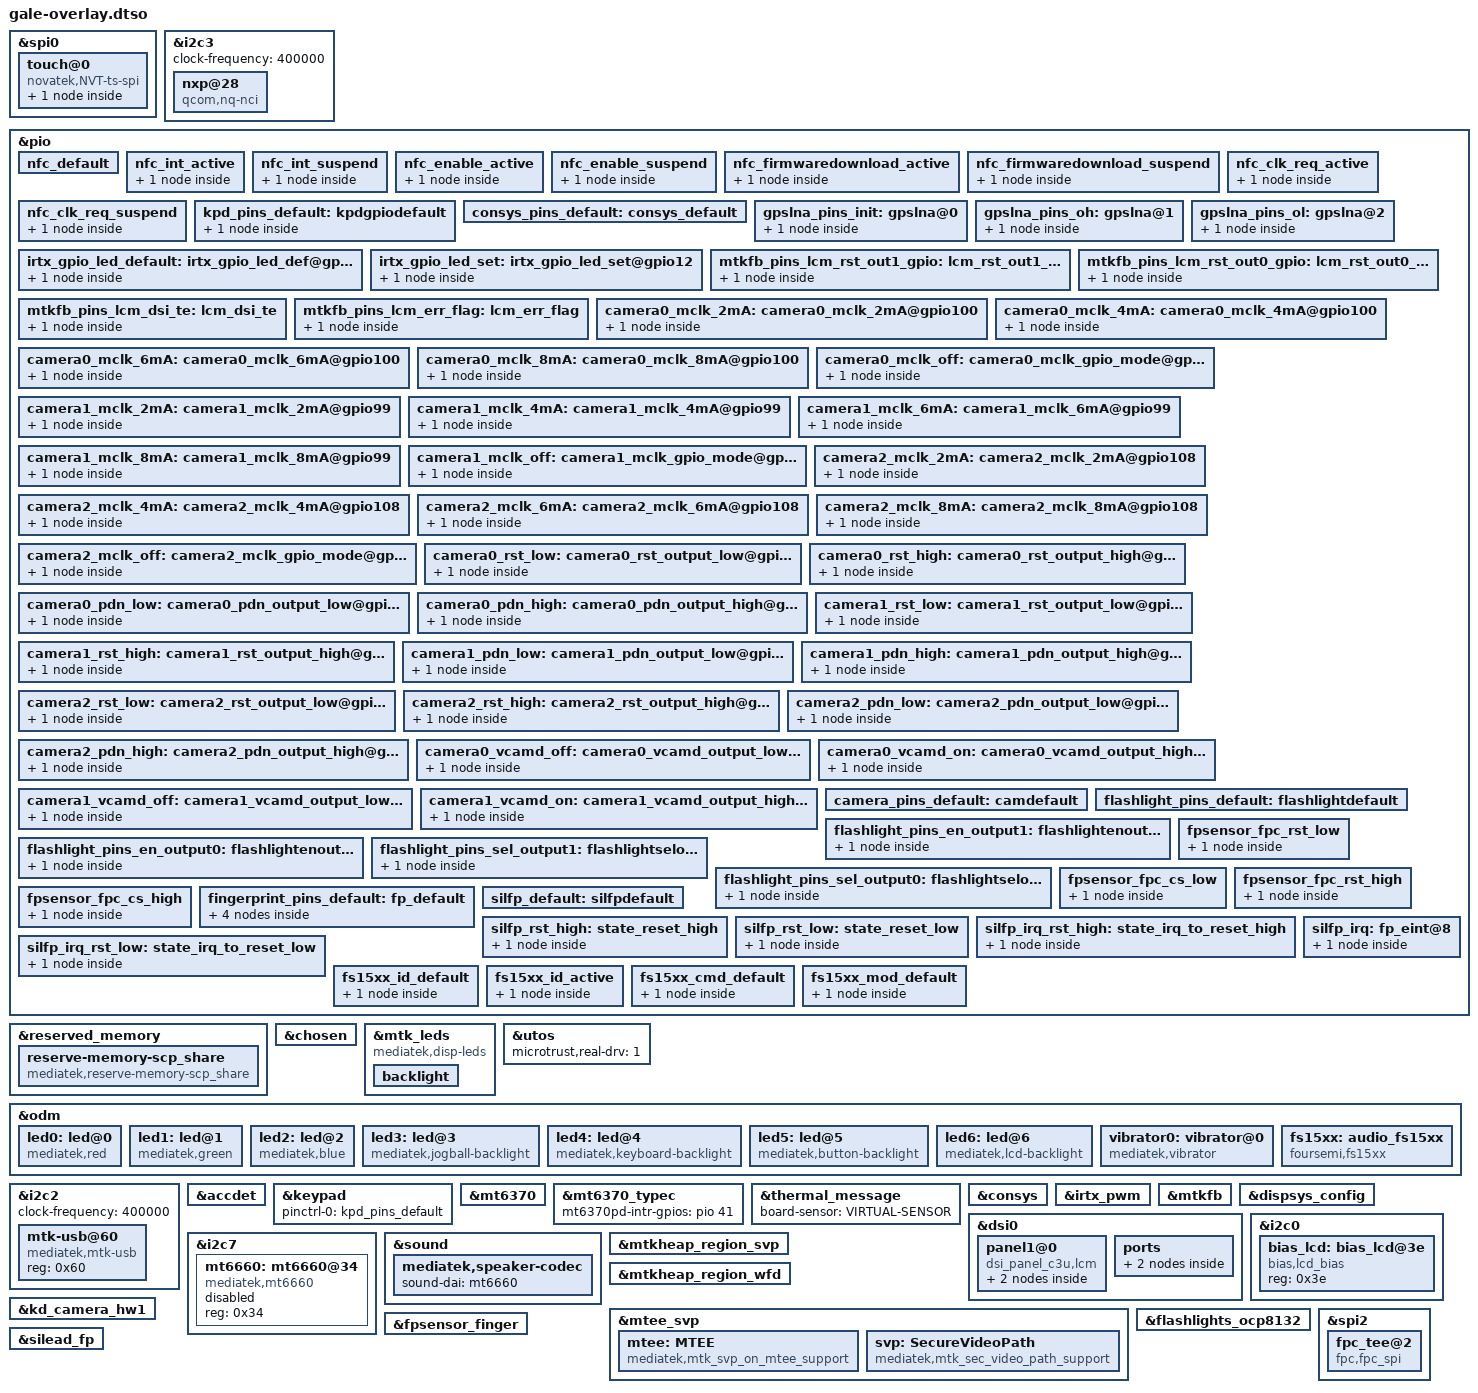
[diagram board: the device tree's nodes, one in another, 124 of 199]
// SPDX-License-Identifier: GPL-2.0
/*
 * Copyright (c) 2019 MediaTek Inc.
 */

/dts-v1/;
/plugin/;
#include <dt-bindings/interrupt-controller/irq.h>
#include <dt-bindings/interrupt-controller/arm-gic.h>
#include <dt-bindings/pinctrl/mt6768-pinfunc.h>

&spi0 {
	status = "okay";
	#address-cells = <1>;
	#size-cells = <0>;
	touch@0 {
		compatible = "novatek,NVT-ts-spi", "focaltech,fts", "omnivision,tcm-spi", "chipone-tddi";
		reg = <0x0>;
		status = "ok";
		spi-max-frequency = <0x927c00>;
		chipone,rst-gpio = <&pio 92 0>;
		chipone,irq-gpio = <&pio 1 0x2001>;
		chipone,x-res = <719>;
		chipone,y-res = <1599>;
		chipone,touch-charger-detect-enable;
		chipone,touch-charger-detect-type = "notify";
		chipone,touch-charger-detect-psy-name = "usb";
		chipone,touch-charger-detect-psp = "POWER_SUPPLY_PROP_ONLINE";
		chipone,touch-charger-detect-psp-poll-interval = <1000>;
		chipone,touch-earjack-detect-enable;
		chipone,touch-earjack-state-filepath = "/sys/bus/platform/drivers/Accdet_Driver/state";
		chipone,touch-earjack-poll-interval = <1000>;
		chipone,test-reset-pin;
		chipone,test-int-pin;
		chipone,test-rawdata;
		chipone,test-rawdata-frames = <1>;
		chipone,rawdata-min = <100>;
		chipone,rawdata-max = <10000>;
		chipone,test-noise;
		chipone,test-noise-frames = <50>;
		chipone,noise-max = <1000>;
		chipone,test-open;
		chipone,open-min = <200>;
		chipone,test-short;
		chipone,short-min = <200>;
		chipone,test-compensate-cap;
		chipone,compensate-cap-min = <1>;
		chipone,compensate-cap-max = <127>;
		chipone,test-gesture-rawdata;
		chipone,test-gesture-rawdata-frames = <1>;
		chipone,gesture-rawdata-min = <100>;
		chipone,gesture-rawdata-max = <10000>;
		chipone,test-gesture-lp-rawdata;
		chipone,test-gesture-lp-rawdata-frames = <1>;
		chipone,gesture-lp-rawdata-min = <100>;
		chipone,gesture-lp-rawdata-max = <10000>;
		chipone,test-gesture-noise;
		chipone,test-gesture-noise-frames = <50>;
		chipone,gesture-noise-max = <1000>;
		chipone,test-gesture-lp-noise;
		chipone,test-gesture-lp-noise-frames = <50>;
		chipone,gesture-lp-noise-max = <1000>;
		focaltech,reset-gpio = <&pio 92 0>;
		focaltech,irq-gpio = <&pio 1 0x2001>;
		focaltech,max-touch-number = <10>;
		focaltech,display-coords = <0 0 719 1599>;
		novatek,reset-gpio = <&pio 92 0>;
		novatek,irq-gpio = <&pio 1 0x2001>;
		novatek,mp-support-dt;
		omnivision,irq-gpio = <&pio 1 0x2001>;
		omnivision,reset-gpio = <&pio 92 0>;
		omnivision,spi-mode = <3>;
		novatek-mp-criteria-597D@0 {
			#address-cells = <1>;
			#size-cells = <0>;
			compatible = "novatek-mp-criteria-597D";
			IC_X_CFG_SIZE = <18>;
			IC_Y_CFG_SIZE = <32>;
			IC_KEY_CFG_SIZE = <4>;
			X_Channel = <18>;
			Y_Channel = <32>;
			AIN_X = <0 1 2 3 4 5 6 7 8 9 10 11 12 13 14 15 16 17>;
			AIN_Y = <0 1 2 3 4 5 6 7 8 9 10 11 12 13 14 15 16 17 18 19 20 21 22 23 24 25 26 27 28 29 30 31>;
			AIN_KEY = <0 1 2 255>;
			PS_Config_Lmt_Short_Rawdata_P = <0x36b8 0x36b8 0x36b8 0x36b8 0x36b8 0x36b8 0x36b8 0x36b8 0x36b8 0x36b8 0x36b8 0x36b8 0x36b8 0x36b8 0x36b8 0x36b8 0x36b8 0x36b8 0x36b8 0x36b8 0x36b8 0x36b8 0x36b8 0x36b8 0x36b8 0x36b8 0x36b8 0x36b8 0x36b8 0x36b8 0x36b8 0x36b8 0x36b8 0x36b8 0x36b8 0x36b8 0x36b8 0x36b8 0x36b8 0x36b8 0x36b8 0x36b8 0x36b8 0x36b8 0x36b8 0x36b8 0x36b8 0x36b8 0x36b8 0x36b8 0x36b8 0x36b8 0x36b8 0x36b8 0x36b8 0x36b8 0x36b8 0x36b8 0x36b8 0x36b8 0x36b8 0x36b8 0x36b8 0x36b8 0x36b8 0x36b8 0x36b8 0x36b8 0x36b8 0x36b8 0x36b8 0x36b8 0x36b8 0x36b8 0x36b8 0x36b8 0x36b8 0x36b8 0x36b8 0x36b8 0x36b8 0x36b8 0x36b8 0x36b8 0x36b8 0x36b8 0x36b8 0x36b8 0x36b8 0x36b8 0x36b8 0x36b8 0x36b8 0x36b8 0x36b8 0x36b8 0x36b8 0x36b8 0x36b8 0x36b8 0x36b8 0x36b8 0x36b8 0x36b8 0x36b8 0x36b8 0x36b8 0x36b8 0x36b8 0x36b8 0x36b8 0x36b8 0x36b8 0x36b8 0x36b8 0x36b8 0x36b8 0x36b8 0x36b8 0x36b8 0x36b8 0x36b8 0x36b8 0x36b8 0x36b8 0x36b8 0x36b8 0x36b8 0x36b8 0x36b8 0x36b8 0x36b8 0x36b8 0x36b8 0x36b8 0x36b8 0x36b8 0x36b8 0x36b8 0x36b8 0x36b8 0x36b8 0x36b8 0x36b8 0x36b8 0x36b8 0x36b8 0x36b8 0x36b8 0x36b8 0x36b8 0x36b8 0x36b8 0x36b8 0x36b8 0x36b8 0x36b8 0x36b8 0x36b8 0x36b8 0x36b8 0x36b8 0x36b8 0x36b8 0x36b8 0x36b8 0x36b8 0x36b8 0x36b8 0x36b8 0x36b8 0x36b8 0x36b8 0x36b8 0x36b8 0x36b8 0x36b8 0x36b8 0x36b8 0x36b8 0x36b8 0x36b8 0x36b8 0x36b8 0x36b8 0x36b8 0x36b8 0x36b8 0x36b8 0x36b8 0x36b8 0x36b8 0x36b8 0x36b8 0x36b8 0x36b8 0x36b8 0x36b8 0x36b8 0x36b8 0x36b8 0x36b8 0x36b8 0x36b8 0x36b8 0x36b8 0x36b8 0x36b8 0x36b8 0x36b8 0x36b8 0x36b8 0x36b8 0x36b8 0x36b8 0x36b8 0x36b8 0x36b8 0x36b8 0x36b8 0x36b8 0x36b8 0x36b8 0x36b8 0x36b8 0x36b8 0x36b8 0x36b8 0x36b8 0x36b8 0x36b8 0x36b8 0x36b8 0x36b8 0x36b8 0x36b8 0x36b8 0x36b8 0x36b8 0x36b8 0x36b8 0x36b8 0x36b8 0x36b8 0x36b8 0x36b8 0x36b8 0x36b8 0x36b8 0x36b8 0x36b8 0x36b8 0x36b8 0x36b8 0x36b8 0x36b8 0x36b8 0x36b8 0x36b8 0x36b8 0x36b8 0x36b8 0x36b8 0x36b8 0x36b8 0x36b8 0x36b8 0x36b8 0x36b8 0x36b8 0x36b8 0x36b8 0x36b8 0x36b8 0x36b8 0x36b8 0x36b8 0x36b8 0x36b8 0x36b8 0x36b8 0x36b8 0x36b8 0x36b8 0x36b8 0x36b8 0x36b8 0x36b8 0x36b8 0x36b8 0x36b8 0x36b8 0x36b8 0x36b8 0x36b8 0x36b8 0x36b8 0x36b8 0x36b8 0x36b8 0x36b8 0x36b8 0x36b8 0x36b8 0x36b8 0x36b8 0x36b8 0x36b8 0x36b8 0x36b8 0x36b8 0x36b8 0x36b8 0x36b8 0x36b8 0x36b8 0x36b8 0x36b8 0x36b8 0x36b8 0x36b8 0x36b8 0x36b8 0x36b8 0x36b8 0x36b8 0x36b8 0x36b8 0x36b8 0x36b8 0x36b8 0x36b8 0x36b8 0x36b8 0x36b8 0x36b8 0x36b8 0x36b8 0x36b8 0x36b8 0x36b8 0x36b8 0x36b8 0x36b8 0x36b8 0x36b8 0x36b8 0x36b8 0x36b8 0x36b8 0x36b8 0x36b8 0x36b8 0x36b8 0x36b8 0x36b8 0x36b8 0x36b8 0x36b8 0x36b8 0x36b8 0x36b8 0x36b8 0x36b8 0x36b8 0x36b8 0x36b8 0x36b8 0x36b8 0x36b8 0x36b8 0x36b8 0x36b8 0x36b8 0x36b8 0x36b8 0x36b8 0x36b8 0x36b8 0x36b8 0x36b8 0x36b8 0x36b8 0x36b8 0x36b8 0x36b8 0x36b8 0x36b8 0x36b8 0x36b8 0x36b8 0x36b8 0x36b8 0x36b8 0x36b8 0x36b8 0x36b8 0x36b8 0x36b8 0x36b8 0x36b8 0x36b8 0x36b8 0x36b8 0x36b8 0x36b8 0x36b8 0x36b8 0x36b8 0x36b8 0x36b8 0x36b8 0x36b8 0x36b8 0x36b8 0x36b8 0x36b8 0x36b8 0x36b8 0x36b8 0x36b8 0x36b8 0x36b8 0x36b8 0x36b8 0x36b8 0x36b8 0x36b8 0x36b8 0x36b8 0x36b8 0x36b8 0x36b8 0x36b8 0x36b8 0x36b8 0x36b8 0x36b8 0x36b8 0x36b8 0x36b8 0x36b8 0x36b8 0x36b8 0x36b8 0x36b8 0x36b8 0x36b8 0x36b8 0x36b8 0x36b8 0x36b8 0x36b8 0x36b8 0x36b8 0x36b8 0x36b8 0x36b8 0x36b8 0x36b8 0x36b8 0x36b8 0x36b8 0x36b8 0x36b8 0x36b8 0x36b8 0x36b8 0x36b8 0x36b8 0x36b8 0x36b8 0x36b8 0x36b8 0x36b8 0x36b8 0x36b8 0x36b8 0x36b8 0x36b8 0x36b8 0x36b8 0x36b8 0x36b8 0x36b8 0x36b8 0x36b8 0x36b8 0x36b8 0x36b8 0x36b8 0x36b8 0x36b8 0x36b8 0x36b8 0x36b8 0x36b8 0x36b8 0x36b8 0x36b8 0x36b8 0x36b8 0x36b8 0x36b8 0x36b8 0x36b8 0x36b8 0x36b8 0x36b8 0x36b8 0x36b8 0x36b8 0x36b8 0x36b8 0x36b8 0x36b8 0x36b8 0x36b8 0x36b8 0x36b8 0x36b8 0x36b8 0x36b8 0x36b8 0x36b8 0x36b8 0x36b8 0x36b8 0x36b8 0x36b8 0x36b8 0x36b8 0x36b8 0x36b8 0x36b8 0x36b8 0x36b8 0x36b8 0x36b8 0x36b8 0x36b8 0x36b8 0x36b8 0x36b8 0x36b8 0x36b8 0x36b8 0x36b8 0x36b8 0x36b8 0x36b8 0x36b8 0x36b8 0x36b8 0x36b8 0x36b8 0x36b8 0x36b8 0x36b8 0x36b8 0x36b8 0x36b8 0x36b8 0x36b8 0x36b8 0x36b8 0x36b8 0x36b8 0x36b8 0x36b8 0x36b8 0x36b8 0x36b8 0x36b8 0x36b8 0x36b8 0x36b8 0x36b8 0x36b8>;
			PS_Config_Lmt_Short_Rawdata_N = <0x2774 0x2774 0x2774 0x2774 0x2774 0x2774 0x2774 0x2774 0x2774 0x2774 0x2774 0x2774 0x2774 0x2774 0x2774 0x2774 0x2774 0x2774 0x2774 0x2774 0x2774 0x2774 0x2774 0x2774 0x2774 0x2774 0x2774 0x2774 0x2774 0x2774 0x2774 0x2774 0x2774 0x2774 0x2774 0x2774 0x2774 0x2774 0x2774 0x2774 0x2774 0x2774 0x2774 0x2774 0x2774 0x2774 0x2774 0x2774 0x2774 0x2774 0x2774 0x2774 0x2774 0x2774 0x2774 0x2774 0x2774 0x2774 0x2774 0x2774 0x2774 0x2774 0x2774 0x2774 0x2774 0x2774 0x2774 0x2774 0x2774 0x2774 0x2774 0x2774 0x2774 0x2774 0x2774 0x2774 0x2774 0x2774 0x2774 0x2774 0x2774 0x2774 0x2774 0x2774 0x2774 0x2774 0x2774 0x2774 0x2774 0x2774 0x2774 0x2774 0x2774 0x2774 0x2774 0x2774 0x2774 0x2774 0x2774 0x2774 0x2774 0x2774 0x2774 0x2774 0x2774 0x2774 0x2774 0x2774 0x2774 0x2774 0x2774 0x2774 0x2774 0x2774 0x2774 0x2774 0x2774 0x2774 0x2774 0x2774 0x2774 0x2774 0x2774 0x2774 0x2774 0x2774 0x2774 0x2774 0x2774 0x2774 0x2774 0x2774 0x2774 0x2774 0x2774 0x2774 0x2774 0x2774 0x2774 0x2774 0x2774 0x2774 0x2774 0x2774 0x2774 0x2774 0x2774 0x2774 0x2774 0x2774 0x2774 0x2774 0x2774 0x2774 0x2774 0x2774 0x2774 0x2774 0x2774 0x2774 0x2774 0x2774 0x2774 0x2774 0x2774 0x2774 0x2774 0x2774 0x2774 0x2774 0x2774 0x2774 0x2774 0x2774 0x2774 0x2774 0x2774 0x2774 0x2774 0x2774 0x2774 0x2774 0x2774 0x2774 0x2774 0x2774 0x2774 0x2774 0x2774 0x2774 0x2774 0x2774 0x2774 0x2774 0x2774 0x2774 0x2774 0x2774 0x2774 0x2774 0x2774 0x2774 0x2774 0x2774 0x2774 0x2774 0x2774 0x2774 0x2774 0x2774 0x2774 0x2774 0x2774 0x2774 0x2774 0x2774 0x2774 0x2774 0x2774 0x2774 0x2774 0x2774 0x2774 0x2774 0x2774 0x2774 0x2774 0x2774 0x2774 0x2774 0x2774 0x2774 0x2774 0x2774 0x2774 0x2774 0x2774 0x2774 0x2774 0x2774 0x2774 0x2774 0x2774 0x2774 0x2774 0x2774 0x2774 0x2774 0x2774 0x2774 0x2774 0x2774 0x2774 0x2774 0x2774 0x2774 0x2774 0x2774 0x2774 0x2774 0x2774 0x2774 0x2774 0x2774 0x2774 0x2774 0x2774 0x2774 0x2774 0x2774 0x2774 0x2774 0x2774 0x2774 0x2774 0x2774 0x2774 0x2774 0x2774 0x2774 0x2774 0x2774 0x2774 0x2774 0x2774 0x2774 0x2774 0x2774 0x2774 0x2774 0x2774 0x2774 0x2774 0x2774 0x2774 0x2774 0x2774 0x2774 0x2774 0x2774 0x2774 0x2774 0x2774 0x2774 0x2774 0x2774 0x2774 0x2774 0x2774 0x2774 0x2774 0x2774 0x2774 0x2774 0x2774 0x2774 0x2774 0x2774 0x2774 0x2774 0x2774 0x2774 0x2774 0x2774 0x2774 0x2774 0x2774 0x2774 0x2774 0x2774 0x2774 0x2774 0x2774 0x2774 0x2774 0x2774 0x2774 0x2774 0x2774 0x2774 0x2774 0x2774 0x2774 0x2774 0x2774 0x2774 0x2774 0x2774 0x2774 0x2774 0x2774 0x2774 0x2774 0x2774 0x2774 0x2774 0x2774 0x2774 0x2774 0x2774 0x2774 0x2774 0x2774 0x2774 0x2774 0x2774 0x2774 0x2774 0x2774 0x2774 0x2774 0x2774 0x2774 0x2774 0x2774 0x2774 0x2774 0x2774 0x2774 0x2774 0x2774 0x2774 0x2774 0x2774 0x2774 0x2774 0x2774 0x2774 0x2774 0x2774 0x2774 0x2774 0x2774 0x2774 0x2774 0x2774 0x2774 0x2774 0x2774 0x2774 0x2774 0x2774 0x2774 0x2774 0x2774 0x2774 0x2774 0x2774 0x2774 0x2774 0x2774 0x2774 0x2774 0x2774 0x2774 0x2774 0x2774 0x2774 0x2774 0x2774 0x2774 0x2774 0x2774 0x2774 0x2774 0x2774 0x2774 0x2774 0x2774 0x2774 0x2774 0x2774 0x2774 0x2774 0x2774 0x2774 0x2774 0x2774 0x2774 0x2774 0x2774 0x2774 0x2774 0x2774 0x2774 0x2774 0x2774 0x2774 0x2774 0x2774 0x2774 0x2774 0x2774 0x2774 0x2774 0x2774 0x2774 0x2774 0x2774 0x2774 0x2774 0x2774 0x2774 0x2774 0x2774 0x2774 0x2774 0x2774 0x2774 0x2774 0x2774 0x2774 0x2774 0x2774 0x2774 0x2774 0x2774 0x2774 0x2774 0x2774 0x2774 0x2774 0x2774 0x2774 0x2774 0x2774 0x2774 0x2774 0x2774 0x2774 0x2774 0x2774 0x2774 0x2774 0x2774 0x2774 0x2774 0x2774 0x2774 0x2774 0x2774 0x2774 0x2774 0x2774 0x2774 0x2774 0x2774 0x2774 0x2774 0x2774 0x2774 0x2774 0x2774 0x2774 0x2774 0x2774 0x2774 0x2774 0x2774 0x2774 0x2774 0x2774 0x2774 0x2774 0x2774 0x2774 0x2774 0x2774 0x2774 0x2774 0x2774 0x2774 0x2774 0x2774 0x2774 0x2774 0x2774 0x2774 0x2774 0x2774 0x2774 0x2774 0x2774 0x2774 0x2774 0x2774 0x2774 0x2774 0x2774 0x2774 0x2774 0x2774 0x2774 0x2774 0x2774 0x2774 0x2774 0x2774 0x2774 0x2774 0x2774 0x2774 0x2774 0x2774 0x2774 0x2774 0x2774 0x2774 0x2774 0x2774 0x2774 0x2774 0x2774 0x2774 0x2774 0x2774 0x2710 0x2710 0x2710>;
			PS_Config_Lmt_Open_Rawdata_P = <0xa0b 0xa06 0x9d3 0x999 0x963 0x945 0x90e 0x8f5 0xffff 0xffff 0x811 0x821 0x840 0x852 0x874 0x88a 0x8a9 0x8cb 0x984 0x98b 0x974 0x94e 0x92b 0x914 0x904 0x8ee 0x8d7 0x918 0x922 0x92e 0x934 0x93c 0x943 0x942 0x957 0x97f 0xa43 0xa4c 0xa33 0xa0b 0x9e8 0x9ca 0x9b6 0x9a1 0x984 0x89f 0x8a8 0x8ad 0x8b9 0x8c5 0x8cf 0x8d3 0x8de 0x908 0x9b9 0x9d5 0x9c0 0x9a1 0x97f 0x962 0x94e 0x938 0x923 0x947 0x950 0x95b 0x966 0x96f 0x977 0x97b 0x98b 0x9af 0xa48 0xa6c 0xa4d 0xa2a 0x9ff 0x9dd 0x9cc 0x9ae 0x999 0x8f5 0x901 0x907 0x912 0x918 0x91c 0x924 0x937 0x95a 0x9e4 0xa0e 0x9ee 0x9cb 0x9a7 0x988 0x976 0x95f 0x94a 0x9b6 0x9c3 0x9cc 0x9d6 0x9dd 0x9e6 0x9ed 0x9fb 0xa1c 0xa4d 0xa3f 0xa18 0x9f9 0x9cc 0x9b3 0x9af 0x999 0x97e 0x924 0x92e 0x93b 0x938 0x946 0x94c 0x94d 0x96f 0x91c 0x9b6 0x9a1 0x97d 0x95e 0x935 0x91c 0x916 0x8ff 0x8e7 0x9e0 0x9e8 0x9f5 0x9f1 0xa06 0xa10 0xa15 0xa35 0x9fb 0xa8b 0xa6d 0xa49 0xa2e 0xa04 0x9e4 0x9e4 0x9c3 0x9a9 0x98b 0x999 0x99e 0x99b 0x9a4 0x9ae 0x9ac 0x9ce 0x993 0xa27 0xa06 0x9e3 0x9c3 0x99a 0x978 0x976 0x95b 0x945 0xa1b 0xa27 0xa37 0xa2e 0xa38 0xa46 0xa49 0xa62 0xa38 0xb02 0xad6 0xaae 0xa8f 0xa69 0xa4d 0xa42 0xa2a 0xa17 0x9b3 0x9bd 0x9cc 0x9cb 0x9d6 0x9e6 0x9e0 0xa02 0x9e4 0xa88 0xa61 0xa3e 0xa25 0x9fd 0x9e4 0x9d8 0x9bd 0x9a7 0xab1 0xaba 0xaca 0xac6 0xad1 0xadd 0xadc 0xafe 0xaeb 0xb6c 0xb3e 0xb1b 0xafc 0xad6 0xab8 0xaab 0xa96 0xa77 0xa49 0xa4f 0xa5f 0xa53 0xa5b 0xa66 0xa5e 0xa7d 0xa73 0xae3 0xab8 0xa93 0xa76 0xa50 0xa34 0xa2c 0xa17 0x9fc 0xa8e 0xa93 0xa9d 0xa99 0xaa4 0xaab 0xaa8 0xac7 0xac4 0xbcd 0xb9c 0xb73 0xb54 0xb30 0xb0e 0xb07 0xae9 0xad2 0xa3f 0xa4c 0xa57 0xa58 0xa5f 0xa66 0xa5f 0xa7d 0xa8c 0xb3d 0xb0d 0xae6 0xacd 0xaa5 0xa88 0xa81 0xa65 0xa50 0xb00 0xb07 0xb10 0xb0e 0xb17 0xb26 0xb2a 0xb49 0xb61 0xc2c 0xbf8 0xbcb 0xbad 0xb84 0xb62 0xb5b 0xb3d 0xb2c 0xad6 0xadd 0xae7 0xadd 0xae4 0xaf0 0xaf1 0xb11 0xb2d 0xbb2 0xb81 0xb60 0xb3f 0xb0d 0xaed 0xadd 0xac1 0xaaf 0xb5a 0xb62 0xb75 0xb73 0xb7c 0xb84 0xb84 0xba1 0xbc6 0xc8a 0xc60 0xc3d 0xc18 0xbf3 0xbce 0xbb6 0xb9f 0xb81 0xaee 0xaed 0xb02 0xafb 0xb06 0xb0e 0xb07 0xb26 0xb44 0xc1d 0xbec 0xbc9 0xba6 0xb7e 0xb68 0xb59 0xb41 0xb25 0xbbd 0xbc6 0xbd7 0xbd1 0xbd2 0xbe0 0xbdf 0xbff 0xc2c 0xcf0 0xcbc 0xc92 0xc72 0xc49 0xc34 0xc2d 0xc11 0xbed 0xb6c 0xb79 0xb83 0xb7e 0xb8a 0xb92 0xb8c 0xbab 0xbd7 0xc79 0xc48 0xc2b 0xc05 0xbdf 0xbc4 0xbbd 0xba6 0xb8a 0xc2c 0xc39 0xc47 0xc41 0xc4e 0xc59 0xc5d 0xc75 0xca3 0xd6d 0xd3a 0xd0d 0xcf1 0xcc7 0xca7 0xc9c 0xc7d 0xc63 0xbe2 0xbfb 0xc03 0xc06 0xc11 0xc1b 0xc1b 0xc36 0xc59 0xce6 0xcb2 0xc8e 0xc73 0xc4f 0xc2f 0xc1f 0xc0a 0xbf3 0xca0 0xcb2 0xcb8 0xcb7 0xcbf 0xcc9 0xcd0 0xcea 0xd19 0xdec 0xdbf 0xd99 0xd7b 0xd4f 0xd32 0xd20 0xcfe 0xcdc 0xc41 0xc4f 0xc5e 0xc57 0xc59 0xc67 0xc64 0xc83 0xcad 0xd68 0xd3d 0xd19 0xcf8 0xcce 0xcb4 0xca3 0xc8e 0xc6c 0xce9 0xcfe 0xd0b 0xd0f 0xd1a 0xd22 0xd1d 0xd35 0xd5d 0xe35 0xe08 0xddb 0xdb7 0xd8e 0xd79 0xd68 0xd51 0xd29 0xc8d 0xc9b 0xca9 0xcb0 0xcb5 0xcb8 0xcbc 0xcdf 0xd0c 0xe17 0xdec 0xdcd 0xdaa 0xd7d 0xd64 0xd56 0xd35 0xd16 0xd5f 0xd68 0xd79 0xd7b 0xd7f 0xd8b 0xd8d 0xda3 0xdd0 0xe62 0xed9 0xeb4 0xe91 0xe63 0xe3c 0xe2a 0xe09 0xddf 0xd08 0xd1a 0xd24 0xd29 0xd2e 0xd37 0xd39 0xd5f 0xd10 0xd7d 0xdf7 0xdde 0xdbc 0xd9b 0xd7d 0xd6d 0xd4e 0xd32 0xdb8 0xdc8 0xddd 0xde5 0xdef 0xdf7 0xdfb 0xe0b 0xdac 0xe75 0xf15 0xef3 0xecc 0xea3 0xe7c 0xe6b 0xe4b 0xe2a 0xd63 0xd75 0xd83 0xd7f 0xd83 0xd8e 0xd8b 0xda5 0xd3e 0xe00 0xeb1 0xeaa 0xe82 0xe5d 0xe43 0xe32 0xe1a 0xdf7 0xe01 0xe12 0xe1c 0xe20 0xe2e 0xe40 0xe47 0xe44 0xdb5 0x1400 0x1400 0x1400>;
			PS_Config_Lmt_Open_Rawdata_N = <0x44e 0x44b 0x436 0x41d 0x406 0x3f9 0x3e1 0x3d6 0xffff0001 0xffff0001 0x375 0x37c 0x389 0x391 0x39f 0x3a9 0x3b6 0x3c4 0x414 0x417 0x40d 0x3fd 0x3ee 0x3e4 0x3dd 0x3d3 0x3ca 0x3e5 0x3ea 0x3ef 0x3f1 0x3f5 0x3f8 0x3f7 0x400 0x412 0x466 0x469 0x45f 0x44e 0x43f 0x432 0x429 0x420 0x414 0x3b2 0x3b5 0x3b8 0x3bd 0x3c2 0x3c6 0x3c8 0x3cd 0x3df 0x42a 0x436 0x42d 0x420 0x412 0x405 0x3fd 0x3f3 0x3ea 0x3fa 0x3fd 0x402 0x407 0x40b 0x40e 0x410 0x417 0x426 0x468 0x477 0x46a 0x45b 0x448 0x43a 0x433 0x426 0x41d 0x3d6 0x3dc 0x3de 0x3e3 0x3e5 0x3e7 0x3eb 0x3f3 0x402 0x43d 0x44f 0x441 0x432 0x423 0x415 0x40e 0x404 0x3fb 0x429 0x42f 0x433 0x437 0x43a 0x43e 0x441 0x447 0x455 0x46a 0x464 0x453 0x446 0x433 0x428 0x426 0x41d 0x411 0x3eb 0x3ef 0x3f4 0x3f3 0x3f9 0x3fc 0x3fc 0x40b 0x3e7 0x429 0x420 0x411 0x403 0x3f2 0x3e7 0x3e5 0x3db 0x3d0 0x43b 0x43f 0x444 0x442 0x44b 0x450 0x452 0x460 0x447 0x484 0x478 0x468 0x45d 0x44b 0x43d 0x43d 0x42f 0x424 0x417 0x41d 0x41f 0x41e 0x421 0x426 0x425 0x433 0x41a 0x45a 0x44b 0x43c 0x42f 0x41d 0x40f 0x40e 0x402 0x3f9 0x454 0x45a 0x460 0x45d 0x461 0x467 0x468 0x473 0x461 0x4b7 0x4a5 0x493 0x486 0x476 0x46a 0x465 0x45b 0x453 0x428 0x42c 0x433 0x432 0x437 0x43e 0x43b 0x44a 0x43d 0x483 0x472 0x463 0x459 0x448 0x43d 0x438 0x42c 0x423 0x495 0x499 0x49f 0x49e 0x4a2 0x4a8 0x4a7 0x4b6 0x4ae 0x4e5 0x4d1 0x4c2 0x4b5 0x4a5 0x498 0x492 0x489 0x47c 0x468 0x46b 0x472 0x46c 0x470 0x475 0x471 0x47e 0x47a 0x4aa 0x498 0x488 0x47b 0x46b 0x45f 0x45c 0x453 0x447 0x486 0x488 0x48c 0x48a 0x48f 0x492 0x491 0x49e 0x49d 0x50e 0x4f9 0x4e8 0x4db 0x4cb 0x4bd 0x4ba 0x4ad 0x4a3 0x464 0x469 0x46e 0x46f 0x472 0x475 0x472 0x47e 0x485 0x4d1 0x4bc 0x4ab 0x4a1 0x490 0x483 0x480 0x474 0x46b 0x4b7 0x4ba 0x4bd 0x4bd 0x4c0 0x4c7 0x4c9 0x4d6 0x4e0 0x537 0x521 0x50e 0x501 0x4ef 0x4e1 0x4de 0x4d1 0x4c9 0x4a5 0x4a8 0x4ac 0x4a8 0x4ab 0x4b0 0x4b0 0x4be 0x4ca 0x503 0x4ee 0x4e0 0x4d2 0x4bc 0x4ae 0x4a8 0x49c 0x494 0x4dd 0x4e1 0x4e9 0x4e8 0x4ec 0x4ef 0x4ef 0x4fc 0x50b 0x55f 0x54d 0x53e 0x52f 0x51f 0x50f 0x505 0x4fb 0x4ee 0x4af 0x4ae 0x4b7 0x4b4 0x4b9 0x4bd 0x4ba 0x4c7 0x4d4 0x531 0x51c 0x50d 0x4fe 0x4ed 0x4e3 0x4dd 0x4d2 0x4c6 0x508 0x50b 0x513 0x510 0x511 0x517 0x516 0x524 0x537 0x58b 0x575 0x563 0x555 0x544 0x53b 0x538 0x52c 0x51c 0x4e5 0x4ea 0x4ef 0x4ed 0x4f2 0x4f5 0x4f3 0x500 0x513 0x558 0x543 0x537 0x526 0x516 0x50b 0x508 0x4fe 0x4f2 0x537 0x53d 0x543 0x540 0x546 0x54a 0x54c 0x556 0x56a 0x5c1 0x5ab 0x598 0x58c 0x57a 0x56c 0x567 0x55a 0x54f 0x517 0x522 0x526 0x527 0x52c 0x530 0x530 0x53b 0x54a 0x587 0x571 0x561 0x556 0x546 0x538 0x532 0x529 0x51f 0x569 0x571 0x573 0x573 0x576 0x57a 0x57d 0x589 0x59d 0x5f7 0x5e4 0x5d4 0x5c7 0x5b4 0x5a7 0x5a0 0x591 0x583 0x540 0x546 0x54d 0x54a 0x54a 0x550 0x54f 0x55c 0x56e 0x5bf 0x5ac 0x59d 0x58f 0x57d 0x571 0x56a 0x561 0x553 0x588 0x591 0x597 0x598 0x59d 0x5a1 0x59e 0x5a9 0x5ba 0x616 0x603 0x5f0 0x5e0 0x5cf 0x5c6 0x5bf 0x5b5 0x5a4 0x561 0x567 0x56d 0x570 0x572 0x573 0x575 0x584 0x597 0x60a 0x5f7 0x5ea 0x5db 0x5c8 0x5bd 0x5b7 0x5a9 0x59b 0x5bb 0x5bf 0x5c6 0x5c7 0x5c8 0x5ce 0x5ce 0x5d8 0x5eb 0x62a 0x65d 0x64d 0x63e 0x62a 0x619 0x612 0x604 0x5f2 0x595 0x59d 0x5a1 0x5a4 0x5a6 0x5aa 0x5aa 0x5bb 0x599 0x5c8 0x5fc 0x5f1 0x5e3 0x5d4 0x5c8 0x5c1 0x5b3 0x5a7 0x5e1 0x5e8 0x5f1 0x5f4 0x5f8 0x5fc 0x5fe 0x604 0x5dc 0x632 0x676 0x668 0x657 0x646 0x635 0x62e 0x620 0x612 0x5bc 0x5c4 0x5ca 0x5c8 0x5ca 0x5cf 0x5ce 0x5d9 0x5ad 0x600 0x64c 0x649 0x637 0x628 0x61c 0x615 0x60b 0x5fc 0x600 0x607 0x60c 0x60d 0x613 0x61b 0x61e 0x61d 0x5e0 0xfffffe01 0xfffffe01 0xfffffe01>;
			PS_Config_Lmt_FW_Rawdata_P = <0x464 0x45e 0x461 0x464 0x465 0x46e 0x45e 0x462 0xffff 0xffff 0x469 0x465 0x461 0x464 0x45e 0x464 0x45e 0x460 0x456 0x45b 0x460 0x461 0x462 0x459 0x459 0x462 0x454 0x462 0x45e 0x461 0x467 0x45a 0x46b 0x464 0x468 0x45e 0x464 0x45b 0x45e 0x462 0x469 0x45e 0x457 0x45d 0x45d 0x468 0x460 0x46e 0x46f 0x459 0x462 0x468 0x465 0x460 0x453 0x464 0x468 0x45d 0x464 0x45b 0x462 0x465 0x46b 0x461 0x45e 0x462 0x461 0x464 0x460 0x464 0x464 0x46c 0x461 0x461 0x464 0x462 0x464 0x461 0x45a 0x45e 0x461 0x45d 0x468 0x460 0x45e 0x465 0x456 0x45e 0x45b 0x460 0x45b 0x454 0x460 0x456 0x469 0x45e 0x465 0x465 0x460 0x45e 0x460 0x45a 0x45b 0x461 0x460 0x465 0x45e 0x464 0x468 0x45e 0x459 0x469 0x45e 0x457 0x45e 0x45b 0x45e 0x457 0x453 0x45e 0x46b 0x45a 0x464 0x45b 0x45a 0x456 0x460 0x45e 0x456 0x467 0x462 0x45d 0x461 0x461 0x45e 0x46c 0x465 0x461 0x461 0x465 0x467 0x456 0x465 0x461 0x46b 0x45d 0x46f 0x464 0x459 0x46e 0x45b 0x45e 0x462 0x464 0x465 0x457 0x462 0x45b 0x461 0x464 0x45d 0x45e 0x46b 0x460 0x46b 0x462 0x453 0x46e 0x456 0x468 0x44f 0x460 0x470 0x462 0x45d 0x460 0x45b 0x45a 0x465 0x462 0x45d 0x464 0x46e 0x45e 0x45d 0x465 0x462 0x461 0x469 0x467 0x457 0x457 0x457 0x457 0x468 0x468 0x461 0x45e 0x450 0x459 0x464 0x461 0x45b 0x464 0x46c 0x456 0x46b 0x45d 0x460 0x462 0x460 0x461 0x460 0x46c 0x45d 0x452 0x45a 0x460 0x464 0x45e 0x461 0x468 0x462 0x45b 0x465 0x46b 0x45b 0x460 0x469 0x464 0x45a 0x44d 0x46f 0x46b 0x460 0x467 0x461 0x464 0x45e 0x45a 0x45b 0x465 0x462 0x469 0x465 0x45d 0x464 0x46e 0x45a 0x46b 0x467 0x460 0x461 0x45a 0x457 0x45e 0x46c 0x462 0x461 0x467 0x468 0x461 0x46e 0x44d 0x456 0x45b 0x464 0x461 0x456 0x45e 0x454 0x461 0x465 0x45d 0x45d 0x469 0x460 0x45d 0x464 0x464 0x468 0x460 0x45d 0x457 0x462 0x45a 0x45d 0x460 0x46f 0x45d 0x459 0x461 0x453 0x469 0x462 0x464 0x464 0x45d 0x462 0x468 0x45b 0x46c 0x460 0x45e 0x46b 0x45d 0x465 0x46f 0x462 0x460 0x45e 0x454 0x465 0x462 0x454 0x45e 0x45b 0x459 0x465 0x460 0x460 0x454 0x470 0x460 0x469 0x456 0x462 0x459 0x46b 0x469 0x457 0x46c 0x462 0x464 0x46b 0x456 0x45e 0x453 0x462 0x460 0x44f 0x45e 0x45b 0x460 0x46e 0x456 0x44c 0x462 0x461 0x465 0x462 0x460 0x45b 0x465 0x467 0x454 0x45a 0x460 0x470 0x462 0x45b 0x460 0x45e 0x453 0x462 0x45d 0x461 0x459 0x45d 0x45b 0x459 0x465 0x46b 0x46f 0x461 0x450 0x45a 0x459 0x462 0x469 0x45d 0x461 0x45e 0x45e 0x452 0x45b 0x462 0x462 0x45b 0x459 0x461 0x45d 0x46b 0x45a 0x469 0x45d 0x457 0x470 0x45b 0x46b 0x467 0x45e 0x470 0x461 0x45b 0x45a 0x45e 0x465 0x460 0x462 0x465 0x464 0x460 0x46e 0x460 0x464 0x46b 0x45e 0x45a 0x457 0x45b 0x46c 0x464 0x462 0x45d 0x45e 0x467 0x456 0x453 0x46f 0x464 0x469 0x46f 0x456 0x461 0x465 0x45e 0x456 0x457 0x450 0x457 0x459 0x45e 0x45e 0x461 0x45a 0x45e 0x45b 0x465 0x45e 0x45e 0x457 0x460 0x45a 0x457 0x461 0x45e 0x460 0x459 0x464 0x467 0x467 0x46b 0x459 0x457 0x45d 0x468 0x460 0x45d 0x462 0x456 0x461 0x45e 0x45d 0x461 0x465 0x464 0x461 0x464 0x454 0x457 0x459 0x460 0x465 0x45e 0x467 0x454 0x469 0x468 0x45b 0x467 0x467 0x460 0x461 0x45b 0x462 0x45a 0x45d 0x469 0x469 0x45e 0x461 0x44b 0x464 0x461 0x462 0x460 0x469 0x464 0x468 0x45d 0x462 0x467 0x469 0x460 0x453 0x44d 0x45d 0x46c 0x46c 0x461 0x46c 0x45d 0x464 0x459 0x450 0x45a 0x465 0x475 0x476 0x457 0x467 0x45e 0x465 0x45d 0x462 0x461 0x460 0x468 0x464 0x467 0x464 0x461 0x459 0x464 0x465 0x469 0x462 0x461 0x462 0x464 0x462 0x460 0x465 0x45d 0x462 0x45d 0x468 0x459 0x454 0x462 0x462 0x45b 0x467 0x45e 0x459 0x45e 0x459 0x45b 0x459 0x460 0x464 0x46c 0x45e 0x459 0x465 0xf00 0xf00 0xf00>;
			PS_Config_Lmt_FW_Rawdata_N = <0x1e1 0x1df 0x1e0 0x1e1 0x1e2 0x1e6 0x1df 0x1e1 0xffff0001 0xffff0001 0x1e4 0x1e2 0x1e0 0x1e1 0x1df 0x1e1 0x1df 0x1e0 0x1db 0x1de 0x1e0 0x1e0 0x1e1 0x1dd 0x1dd 0x1e1 0x1db 0x1e1 0x1df 0x1e0 0x1e3 0x1dd 0x1e4 0x1e1 0x1e3 0x1df 0x1e1 0x1de 0x1df 0x1e1 0x1e4 0x1df 0x1dc 0x1de 0x1de 0x1e3 0x1e0 0x1e6 0x1e6 0x1dd 0x1e1 0x1e3 0x1e2 0x1e0 0x1da 0x1e1 0x1e3 0x1de 0x1e1 0x1de 0x1e1 0x1e2 0x1e4 0x1e0 0x1df 0x1e1 0x1e0 0x1e1 0x1e0 0x1e1 0x1e1 0x1e5 0x1e0 0x1e0 0x1e1 0x1e1 0x1e1 0x1e0 0x1dd 0x1df 0x1e0 0x1de 0x1e3 0x1e0 0x1df 0x1e2 0x1db 0x1df 0x1de 0x1e0 0x1de 0x1db 0x1e0 0x1db 0x1e4 0x1df 0x1e2 0x1e2 0x1e0 0x1df 0x1e0 0x1dd 0x1de 0x1e0 0x1e0 0x1e2 0x1df 0x1e1 0x1e3 0x1df 0x1dd 0x1e4 0x1df 0x1dc 0x1df 0x1de 0x1df 0x1dc 0x1da 0x1df 0x1e4 0x1dd 0x1e1 0x1de 0x1dd 0x1db 0x1e0 0x1df 0x1db 0x1e3 0x1e1 0x1de 0x1e0 0x1e0 0x1df 0x1e5 0x1e2 0x1e0 0x1e0 0x1e2 0x1e3 0x1db 0x1e2 0x1e0 0x1e4 0x1de 0x1e6 0x1e1 0x1dd 0x1e6 0x1de 0x1df 0x1e1 0x1e1 0x1e2 0x1dc 0x1e1 0x1de 0x1e0 0x1e1 0x1de 0x1df 0x1e4 0x1e0 0x1e4 0x1e1 0x1da 0x1e6 0x1db 0x1e3 0x1d8 0x1e0 0x1e7 0x1e1 0x1de 0x1e0 0x1de 0x1dd 0x1e2 0x1e1 0x1de 0x1e1 0x1e6 0x1df 0x1de 0x1e2 0x1e1 0x1e0 0x1e4 0x1e3 0x1dc 0x1dc 0x1dc 0x1dc 0x1e3 0x1e3 0x1e0 0x1df 0x1d9 0x1dd 0x1e1 0x1e0 0x1de 0x1e1 0x1e5 0x1db 0x1e4 0x1de 0x1e0 0x1e1 0x1e0 0x1e0 0x1e0 0x1e5 0x1de 0x1da 0x1dd 0x1e0 0x1e1 0x1df 0x1e0 0x1e3 0x1e1 0x1de 0x1e2 0x1e4 0x1de 0x1e0 0x1e4 0x1e1 0x1dd 0x1d8 0x1e6 0x1e4 0x1e0 0x1e3 0x1e0 0x1e1 0x1df 0x1dd 0x1de 0x1e2 0x1e1 0x1e4 0x1e2 0x1de 0x1e1 0x1e6 0x1dd 0x1e4 0x1e3 0x1e0 0x1e0 0x1dd 0x1dc 0x1df 0x1e5 0x1e1 0x1e0 0x1e3 0x1e3 0x1e0 0x1e6 0x1d8 0x1db 0x1de 0x1e1 0x1e0 0x1db 0x1df 0x1db 0x1e0 0x1e2 0x1de 0x1de 0x1e4 0x1e0 0x1de 0x1e1 0x1e1 0x1e3 0x1e0 0x1de 0x1dc 0x1e1 0x1dd 0x1de 0x1e0 0x1e6 0x1de 0x1dd 0x1e0 0x1da 0x1e4 0x1e1 0x1e1 0x1e1 0x1de 0x1e1 0x1e3 0x1de 0x1e5 0x1e0 0x1df 0x1e4 0x1de 0x1e2 0x1e6 0x1e1 0x1e0 0x1df 0x1db 0x1e2 0x1e1 0x1db 0x1df 0x1de 0x1dd 0x1e2 0x1e0 0x1e0 0x1db 0x1e7 0x1e0 0x1e4 0x1db 0x1e1 0x1dd 0x1e4 0x1e4 0x1dc 0x1e5 0x1e1 0x1e1 0x1e4 0x1db 0x1df 0x1da 0x1e1 0x1e0 0x1d8 0x1df 0x1de 0x1e0 0x1e6 0x1db 0x1d7 0x1e1 0x1e0 0x1e2 0x1e1 0x1e0 0x1de 0x1e2 0x1e3 0x1db 0x1dd 0x1e0 0x1e7 0x1e1 0x1de 0x1e0 0x1df 0x1da 0x1e1 0x1de 0x1e0 0x1dd 0x1de 0x1de 0x1dd 0x1e2 0x1e4 0x1e6 0x1e0 0x1d9 0x1dd 0x1dd 0x1e1 0x1e4 0x1de 0x1e0 0x1df 0x1df 0x1da 0x1de 0x1e1 0x1e1 0x1de 0x1dd 0x1e0 0x1de 0x1e4 0x1dd 0x1e4 0x1de 0x1dc 0x1e7 0x1de 0x1e4 0x1e3 0x1df 0x1e7 0x1e0 0x1de 0x1dd 0x1df 0x1e2 0x1e0 0x1e1 0x1e2 0x1e1 0x1e0 0x1e6 0x1e0 0x1e1 0x1e4 0x1df 0x1dd 0x1dc 0x1de 0x1e5 0x1e1 0x1e1 0x1de 0x1df 0x1e3 0x1db 0x1da 0x1e6 0x1e1 0x1e4 0x1e6 0x1db 0x1e0 0x1e2 0x1df 0x1db 0x1dc 0x1d9 0x1dc 0x1dd 0x1df 0x1df 0x1e0 0x1dd 0x1df 0x1de 0x1e2 0x1df 0x1df 0x1dc 0x1e0 0x1dd 0x1dc 0x1e0 0x1df 0x1e0 0x1dd 0x1e1 0x1e3 0x1e3 0x1e4 0x1dd 0x1dc 0x1de 0x1e3 0x1e0 0x1de 0x1e1 0x1db 0x1e0 0x1df 0x1de 0x1e0 0x1e2 0x1e1 0x1e0 0x1e1 0x1db 0x1dc 0x1dd 0x1e0 0x1e2 0x1df 0x1e3 0x1db 0x1e4 0x1e3 0x1de 0x1e3 0x1e3 0x1e0 0x1e0 0x1de 0x1e1 0x1dd 0x1de 0x1e4 0x1e4 0x1df 0x1e0 0x1d7 0x1e1 0x1e0 0x1e1 0x1e0 0x1e4 0x1e1 0x1e3 0x1de 0x1e1 0x1e3 0x1e4 0x1e0 0x1da 0x1d8 0x1de 0x1e5 0x1e5 0x1e0 0x1e5 0x1de 0x1e1 0x1dd 0x1d9 0x1dd 0x1e2 0x1e9 0x1e9 0x1dc 0x1e3 0x1df 0x1e2 0x1de 0x1e1 0x1e0 0x1e0 0x1e3 0x1e1 0x1e3 0x1e1 0x1e0 0x1dd 0x1e1 0x1e2 0x1e4 0x1e1 0x1e0 0x1e1 0x1e1 0x1e1 0x1e0 0x1e2 0x1de 0x1e1 0x1de 0x1e3 0x1dd 0x1db 0x1e1 0x1e1 0x1de 0x1e3 0x1df 0x1dd 0x1df 0x1dd 0x1de 0x1dd 0x1e0 0x1e1 0x1e5 0x1df 0x1dd 0x1e2 0xf0 0xf0 0xf0>;
			PS_Config_Lmt_FW_CC_P = <0x5b 0x5b 0x59 0x56 0x54 0x52 0x50 0x50 0xffff 0xffff 0x4e 0x4e 0x51 0x52 0x55 0x56 0x59 0x5b 0x5c 0x5b 0x56 0x55 0x54 0x52 0x50 0x4e 0x4d 0x4d 0x4e 0x50 0x51 0x52 0x55 0x56 0x5b 0x5c 0x5c 0x5b 0x58 0x56 0x54 0x52 0x51 0x50 0x4e 0x4e 0x50 0x51 0x52 0x55 0x58 0x59 0x5b 0x5d 0x5c 0x5b 0x58 0x58 0x55 0x52 0x51 0x50 0x4e 0x4e 0x4e 0x51 0x52 0x54 0x56 0x58 0x5b 0x5d 0x5c 0x5b 0x59 0x58 0x56 0x54 0x52 0x50 0x50 0x50 0x50 0x52 0x55 0x56 0x59 0x59 0x5c 0x5d 0x5d 0x5d 0x5b 0x5b 0x59 0x58 0x54 0x52 0x51 0x50 0x51 0x52 0x55 0x58 0x59 0x5b 0x5c 0x5f 0x5d 0x5b 0x59 0x54 0x52 0x51 0x50 0x4e 0x4d 0x4e 0x50 0x51 0x52 0x55 0x56 0x5c 0x5d 0x5d 0x5c 0x5b 0x58 0x52 0x51 0x50 0x4e 0x4d 0x4b 0x4d 0x4e 0x50 0x51 0x52 0x54 0x59 0x5c 0x5c 0x5c 0x5b 0x58 0x52 0x52 0x50 0x50 0x4e 0x4d 0x4e 0x50 0x51 0x52 0x54 0x56 0x5b 0x5c 0x5d 0x5d 0x5b 0x58 0x54 0x52 0x51 0x50 0x4e 0x4d 0x4e 0x50 0x51 0x51 0x54 0x55 0x59 0x5b 0x5c 0x5f 0x5b 0x58 0x54 0x52 0x51 0x50 0x50 0x4d 0x50 0x51 0x52 0x52 0x54 0x56 0x5b 0x5c 0x5f 0x5d 0x5b 0x59 0x54 0x52 0x52 0x51 0x50 0x4e 0x50 0x52 0x52 0x54 0x55 0x58 0x5b 0x5d 0x5f 0x5d 0x5b 0x59 0x55 0x54 0x52 0x52 0x51 0x50 0x52 0x54 0x56 0x56 0x58 0x59 0x5c 0x5d 0x60 0x5d 0x5c 0x59 0x56 0x55 0x52 0x52 0x52 0x51 0x51 0x52 0x54 0x55 0x56 0x58 0x5b 0x5c 0x5f 0x60 0x5d 0x5b 0x58 0x56 0x55 0x54 0x52 0x51 0x52 0x55 0x56 0x56 0x58 0x59 0x5b 0x5d 0x60 0x5f 0x5c 0x5b 0x59 0x58 0x56 0x55 0x54 0x52 0x52 0x54 0x56 0x58 0x58 0x59 0x5b 0x5d 0x5f 0x5f 0x5d 0x5b 0x59 0x59 0x58 0x58 0x55 0x54 0x58 0x59 0x5b 0x5b 0x5b 0x5c 0x5d 0x60 0x63 0x61 0x5d 0x5c 0x5b 0x59 0x59 0x58 0x58 0x55 0x56 0x58 0x59 0x59 0x5b 0x5b 0x5c 0x5f 0x61 0x61 0x5f 0x5c 0x5b 0x5b 0x5b 0x59 0x59 0x58 0x59 0x5b 0x5c 0x5c 0x5c 0x5d 0x5f 0x61 0x63 0x63 0x5f 0x5d 0x5c 0x5b 0x5b 0x5b 0x59 0x59 0x59 0x5b 0x5b 0x5c 0x5c 0x5d 0x5d 0x60 0x63 0x63 0x61 0x5f 0x5d 0x5d 0x5c 0x5c 0x5c 0x5c 0x5c 0x5c 0x5d 0x5d 0x5d 0x5f 0x5f 0x61 0x64 0x66 0x63 0x60 0x5f 0x5f 0x5f 0x5f 0x5d 0x5d 0x5d 0x5d 0x5f 0x5f 0x5f 0x5f 0x60 0x63 0x64 0x68 0x67 0x64 0x64 0x64 0x63 0x64 0x63 0x63 0x63 0x63 0x64 0x64 0x64 0x64 0x66 0x67 0x68 0x68 0x67 0x64 0x64 0x64 0x63 0x63 0x63 0x63 0x63 0x63 0x63 0x63 0x64 0x64 0x64 0x66 0x68 0x6b 0x68 0x67 0x66 0x66 0x66 0x66 0x66 0x66 0x66 0x66 0x66 0x66 0x66 0x66 0x67 0x68 0x6a 0x6b 0x6a 0x67 0x67 0x67 0x67 0x67 0x67 0x67 0x66 0x66 0x66 0x66 0x66 0x67 0x67 0x68 0x6a 0x6d 0x6a 0x68 0x68 0x68 0x68 0x68 0x68 0x68 0x68 0x68 0x68 0x68 0x68 0x68 0x68 0x6a 0x6d 0x6e 0x6d 0x6a 0x6a 0x6a 0x6a 0x6a 0x6a 0x6b 0x6a 0x6a 0x6a 0x6a 0x68 0x6a 0x6a 0x6b 0x6d 0x75 0x6f 0x6d 0x6e 0x6d 0x6d 0x6e 0x6e 0x6e 0x6b 0x6b 0x6b 0x6b 0x6b 0x6b 0x6b 0x6d 0x72 0x71 0x6d 0x6b 0x6b 0x6b 0x6b 0x6b 0x6b 0x6e 0x6d 0x6b 0x6b 0x6b 0x6b 0x6b 0x6b 0x6e 0x71 0x72 0x6f 0x6e 0x6e 0x6e 0x6e 0x6e 0x6e 0x6f 0x6e 0x6d 0x6d 0x6d 0x6d 0x6d 0x6d 0x6e 0x72 0x73 0x72 0x71 0x71 0x71 0x71 0x72 0x72 0x72 0x6f 0x6e 0x6e 0x6e 0x6e 0x6e 0x6d 0x6f 0x73 0x13a 0x13a 0x13a>;
			PS_Config_Lmt_FW_CC_N = <0x28 0x28 0x28 0x27 0x25 0x25 0x23 0x23 0xffff0001 0xffff0001 0x23 0x23 0x24 0x25 0x26 0x27 0x28 0x28 0x29 0x28 0x27 0x26 0x25 0x25 0x23 0x23 0x22 0x22 0x23 0x23 0x24 0x25 0x26 0x27 0x28 0x29 0x29 0x28 0x27 0x27 0x25 0x25 0x24 0x23 0x23 0x23 0x23 0x24 0x25 0x26 0x27 0x28 0x28 0x2a 0x29 0x28 0x27 0x27 0x26 0x25 0x24 0x23 0x23 0x23 0x23 0x24 0x25 0x25 0x27 0x27 0x28 0x2a 0x29 0x28 0x28 0x27 0x27 0x25 0x25 0x23 0x23 0x23 0x23 0x25 0x26 0x27 0x28 0x28 0x29 0x2a 0x2a 0x2a 0x28 0x28 0x28 0x27 0x25 0x25 0x24 0x23 0x24 0x25 0x26 0x27 0x28 0x28 0x29 0x2a 0x2a 0x28 0x28 0x25 0x25 0x24 0x23 0x23 0x22 0x23 0x23 0x24 0x25 0x26 0x27 0x29 0x2a 0x2a 0x29 0x28 0x27 0x25 0x24 0x23 0x23 0x22 0x22 0x22 0x23 0x23 0x24 0x25 0x25 0x28 0x29 0x29 0x29 0x28 0x27 0x25 0x25 0x23 0x23 0x23 0x22 0x23 0x23 0x24 0x25 0x25 0x27 0x28 0x29 0x2a 0x2a 0x28 0x27 0x25 0x25 0x24 0x23 0x23 0x22 0x23 0x23 0x24 0x24 0x25 0x26 0x28 0x28 0x29 0x2a 0x28 0x27 0x25 0x25 0x24 0x23 0x23 0x22 0x23 0x24 0x25 0x25 0x25 0x27 0x28 0x29 0x2a 0x2a 0x28 0x28 0x25 0x25 0x25 0x24 0x23 0x23 0x23 0x25 0x25 0x25 0x26 0x27 0x28 0x2a 0x2a 0x2a 0x28 0x28 0x26 0x25 0x25 0x25 0x24 0x23 0x25 0x25 0x27 0x27 0x27 0x28 0x29 0x2a 0x2b 0x2a 0x29 0x28 0x27 0x26 0x25 0x25 0x25 0x24 0x24 0x25 0x25 0x26 0x27 0x27 0x28 0x29 0x2a 0x2b 0x2a 0x28 0x27 0x27 0x26 0x25 0x25 0x24 0x25 0x26 0x27 0x27 0x27 0x28 0x28 0x2a 0x2b 0x2a 0x29 0x28 0x28 0x27 0x27 0x26 0x25 0x25 0x25 0x25 0x27 0x27 0x27 0x28 0x28 0x2a 0x2a 0x2a 0x2a 0x28 0x28 0x28 0x27 0x27 0x26 0x25 0x27 0x28 0x28 0x28 0x28 0x29 0x2a 0x2b 0x2c 0x2c 0x2a 0x29 0x28 0x28 0x28 0x27 0x27 0x26 0x27 0x27 0x28 0x28 0x28 0x28 0x29 0x2a 0x2c 0x2c 0x2a 0x29 0x28 0x28 0x28 0x28 0x28 0x27 0x28 0x28 0x29 0x29 0x29 0x2a 0x2a 0x2c 0x2c 0x2c 0x2a 0x2a 0x29 0x28 0x28 0x28 0x28 0x28 0x28 0x28 0x28 0x29 0x29 0x2a 0x2a 0x2b 0x2c 0x2c 0x2c 0x2a 0x2a 0x2a 0x29 0x29 0x29 0x29 0x29 0x29 0x2a 0x2a 0x2a 0x2a 0x2a 0x2c 0x2d 0x2d 0x2c 0x2b 0x2a 0x2a 0x2a 0x2a 0x2a 0x2a 0x2a 0x2a 0x2a 0x2a 0x2a 0x2a 0x2b 0x2c 0x2d 0x2f 0x2e 0x2d 0x2d 0x2d 0x2c 0x2d 0x2c 0x2c 0x2c 0x2c 0x2d 0x2d 0x2d 0x2d 0x2d 0x2e 0x2f 0x2f 0x2e 0x2d 0x2d 0x2d 0x2c 0x2c 0x2c 0x2c 0x2c 0x2c 0x2c 0x2c 0x2d 0x2d 0x2d 0x2d 0x2f 0x30 0x2f 0x2e 0x2d 0x2d 0x2d 0x2d 0x2d 0x2d 0x2d 0x2d 0x2d 0x2d 0x2d 0x2d 0x2e 0x2f 0x2f 0x30 0x2f 0x2e 0x2e 0x2e 0x2e 0x2e 0x2e 0x2e 0x2d 0x2d 0x2d 0x2d 0x2d 0x2e 0x2e 0x2f 0x2f 0x30 0x2f 0x2f 0x2f 0x2f 0x2f 0x2f 0x2f 0x2f 0x2f 0x2f 0x2f 0x2f 0x2f 0x2f 0x2f 0x2f 0x30 0x31 0x30 0x2f 0x2f 0x2f 0x2f 0x2f 0x2f 0x30 0x2f 0x2f 0x2f 0x2f 0x2f 0x2f 0x2f 0x30 0x30 0x34 0x32 0x30 0x31 0x30 0x30 0x31 0x31 0x31 0x30 0x30 0x30 0x30 0x30 0x30 0x30 0x30 0x33 0x32 0x30 0x30 0x30 0x30 0x30 0x30 0x30 0x31 0x30 0x30 0x30 0x30 0x30 0x30 0x30 0x31 0x32 0x33 0x32 0x31 0x31 0x31 0x31 0x31 0x31 0x32 0x31 0x30 0x30 0x30 0x30 0x30 0x30 0x31 0x33 0x34 0x33 0x32 0x32 0x32 0x32 0x33 0x33 0x33 0x32 0x31 0x31 0x31 0x31 0x31 0x30 0x32 0x34 0x0 0x0 0x0>;
			PS_Config_Lmt_FW_Diff_P = <0x32 0x32 0x32 0x32 0x32 0x32 0x32 0x32 0xffff 0xffff 0x32 0x32 0x32 0x32 0x32 0x32 0x32 0x32 0x32 0x32 0x32 0x32 0x32 0x32 0x32 0x32 0x32 0x32 0x32 0x32 0x32 0x32 0x32 0x32 0x32 0x32 0x32 0x32 0x32 0x32 0x32 0x32 0x32 0x32 0x32 0x32 0x32 0x32 0x32 0x32 0x32 0x32 0x32 0x32 0x32 0x32 0x32 0x32 0x32 0x32 0x32 0x32 0x32 0x32 0x32 0x32 0x32 0x32 0x32 0x32 0x32 0x32 0x32 0x32 0x32 0x32 0x32 0x32 0x32 0x32 0x32 0x32 0x32 0x32 0x32 0x32 0x32 0x32 0x32 0x32 0x32 0x32 0x32 0x32 0x32 0x32 0x32 0x32 0x32 0x32 0x32 0x32 0x32 0x32 0x32 0x32 0x32 0x32 0x32 0x32 0x32 0x32 0x32 0x32 0x32 0x32 0x32 0x32 0x32 0x32 0x32 0x32 0x32 0x32 0x32 0x32 0x32 0x32 0x32 0x32 0x32 0x32 0x32 0x32 0x32 0x32 0x32 0x32 0x32 0x32 0x32 0x32 0x32 0x32 0x32 0x32 0x32 0x32 0x32 0x32 0x32 0x32 0x32 0x32 0x32 0x32 0x32 0x32 0x32 0x32 0x32 0x32 0x32 0x32 0x32 0x32 0x32 0x32 0x32 0x32 0x32 0x32 0x32 0x32 0x32 0x32 0x32 0x32 0x32 0x32 0x32 0x32 0x32 0x32 0x32 0x32 0x32 0x32 0x32 0x32 0x32 0x32 0x32 0x32 0x32 0x32 0x32 0x32 0x32 0x32 0x32 0x32 0x32 0x32 0x32 0x32 0x32 0x32 0x32 0x32 0x32 0x32 0x32 0x32 0x32 0x32 0x32 0x32 0x32 0x32 0x32 0x32 0x32 0x32 0x32 0x32 0x32 0x32 0x32 0x32 0x32 0x32 0x32 0x32 0x32 0x32 0x32 0x32 0x32 0x32 0x32 0x32 0x32 0x32 0x32 0x32 0x32 0x32 0x32 0x32 0x32 0x32 0x32 0x32 0x32 0x32 0x32 0x32 0x32 0x32 0x32 0x32 0x32 0x32 0x32 0x32 0x32 0x32 0x32 0x32 0x32 0x32 0x32 0x32 0x32 0x32 0x32 0x32 0x32 0x32 0x32 0x32 0x32 0x32 0x32 0x32 0x32 0x32 0x32 0x32 0x32 0x32 0x32 0x32 0x32 0x32 0x32 0x32 0x32 0x32 0x32 0x32 0x32 0x32 0x32 0x32 0x32 0x32 0x32 0x32 0x32 0x32 0x32 0x32 0x32 0x32 0x32 0x32 0x32 0x32 0x32 0x32 0x32 0x32 0x32 0x32 0x32 0x32 0x32 0x32 0x32 0x32 0x32 0x32 0x32 0x32 0x32 0x32 0x32 0x32 0x32 0x32 0x32 0x32 0x32 0x32 0x32 0x32 0x32 0x32 0x32 0x32 0x32 0x32 0x32 0x32 0x32 0x32 0x32 0x32 0x32 0x32 0x32 0x32 0x32 0x32 0x32 0x32 0x32 0x32 0x32 0x32 0x32 0x32 0x32 0x32 0x32 0x32 0x32 0x32 0x32 0x32 0x32 0x32 0x32 0x32 0x32 0x32 0x32 0x32 0x32 0x32 0x32 0x32 0x32 0x32 0x32 0x32 0x32 0x32 0x32 0x32 0x32 0x32 0x32 0x32 0x32 0x32 0x32 0x32 0x32 0x32 0x32 0x32 0x32 0x32 0x32 0x32 0x32 0x32 0x32 0x32 0x32 0x32 0x32 0x32 0x32 0x32 0x32 0x32 0x32 0x32 0x32 0x32 0x32 0x32 0x32 0x32 0x32 0x32 0x32 0x32 0x32 0x32 0x32 0x32 0x32 0x32 0x32 0x32 0x32 0x32 0x32 0x32 0x32 0x32 0x32 0x32 0x32 0x32 0x32 0x32 0x32 0x32 0x32 0x32 0x32 0x32 0x32 0x32 0x32 0x32 0x32 0x32 0x32 0x32 0x32 0x32 0x32 0x32 0x32 0x32 0x32 0x32 0x32 0x32 0x32 0x32 0x32 0x32 0x32 0x32 0x32 0x32 0x32 0x32 0x32 0x32 0x32 0x32 0x32 0x32 0x32 0x32 0x32 0x32 0x32 0x32 0x32 0x32 0x32 0x32 0x32 0x32 0x32 0x32 0x32 0x32 0x32 0x32 0x32 0x32 0x32 0x32 0x32 0x32 0x32 0x32 0x32 0x32 0x32 0x32 0x32 0x32 0x32 0x32 0x32 0x32 0x32 0x32 0x32 0x32 0x32 0x32 0x32 0x32 0x32 0x32 0x32 0x32 0x32 0x32 0x32 0x32 0x32 0x32 0x32 0x32 0x32 0x32 0x32 0x32 0x32 0x32 0x32 0x32 0x32 0x32 0x32 0x32 0x32 0x32 0x32 0x32 0x32 0x32 0x4b 0x4b 0x4b>;
			PS_Config_Lmt_FW_Diff_N = <0xffffffce 0xffffffce 0xffffffce 0xffffffce 0xffffffce 0xffffffce 0xffffffce 0xffffffce 0xffff0001 0xffff0001 0xffffffce 0xffffffce 0xffffffce 0xffffffce 0xffffffce 0xffffffce 0xffffffce 0xffffffce 0xffffffce 0xffffffce 0xffffffce 0xffffffce 0xffffffce 0xffffffce 0xffffffce 0xffffffce 0xffffffce 0xffffffce 0xffffffce 0xffffffce 0xffffffce 0xffffffce 0xffffffce 0xffffffce 0xffffffce 0xffffffce 0xffffffce 0xffffffce 0xffffffce 0xffffffce 0xffffffce 0xffffffce 0xffffffce 0xffffffce 0xffffffce 0xffffffce 0xffffffce 0xffffffce 0xffffffce 0xffffffce 0xffffffce 0xffffffce 0xffffffce 0xffffffce 0xffffffce 0xffffffce 0xffffffce 0xffffffce 0xffffffce 0xffffffce 0xffffffce 0xffffffce 0xffffffce 0xffffffce 0xffffffce 0xffffffce 0xffffffce 0xffffffce 0xffffffce 0xffffffce 0xffffffce 0xffffffce 0xffffffce 0xffffffce 0xffffffce 0xffffffce 0xffffffce 0xffffffce 0xffffffce 0xffffffce 0xffffffce 0xffffffce 0xffffffce 0xffffffce 0xffffffce 0xffffffce 0xffffffce 0xffffffce 0xffffffce 0xffffffce 0xffffffce 0xffffffce 0xffffffce 0xffffffce 0xffffffce 0xffffffce 0xffffffce 0xffffffce 0xffffffce 0xffffffce 0xffffffce 0xffffffce 0xffffffce 0xffffffce 0xffffffce 0xffffffce 0xffffffce 0xffffffce 0xffffffce 0xffffffce 0xffffffce 0xffffffce 0xffffffce 0xffffffce 0xffffffce 0xffffffce 0xffffffce 0xffffffce 0xffffffce 0xffffffce 0xffffffce 0xffffffce 0xffffffce 0xffffffce 0xffffffce 0xffffffce 0xffffffce 0xffffffce 0xffffffce 0xffffffce 0xffffffce 0xffffffce 0xffffffce 0xffffffce 0xffffffce 0xffffffce 0xffffffce 0xffffffce 0xffffffce 0xffffffce 0xffffffce 0xffffffce 0xffffffce 0xffffffce 0xffffffce 0xffffffce 0xffffffce 0xffffffce 0xffffffce 0xffffffce 0xffffffce 0xffffffce 0xffffffce 0xffffffce 0xffffffce 0xffffffce 0xffffffce 0xffffffce 0xffffffce 0xffffffce 0xffffffce 0xffffffce 0xffffffce 0xffffffce 0xffffffce 0xffffffce 0xffffffce 0xffffffce 0xffffffce 0xffffffce 0xffffffce 0xffffffce 0xffffffce 0xffffffce 0xffffffce 0xffffffce 0xffffffce 0xffffffce 0xffffffce 0xffffffce 0xffffffce 0xffffffce 0xffffffce 0xffffffce 0xffffffce 0xffffffce 0xffffffce 0xffffffce 0xffffffce 0xffffffce 0xffffffce 0xffffffce 0xffffffce 0xffffffce 0xffffffce 0xffffffce 0xffffffce 0xffffffce 0xffffffce 0xffffffce 0xffffffce 0xffffffce 0xffffffce 0xffffffce 0xffffffce 0xffffffce 0xffffffce 0xffffffce 0xffffffce 0xffffffce 0xffffffce 0xffffffce 0xffffffce 0xffffffce 0xffffffce 0xffffffce 0xffffffce 0xffffffce 0xffffffce 0xffffffce 0xffffffce 0xffffffce 0xffffffce 0xffffffce 0xffffffce 0xffffffce 0xffffffce 0xffffffce 0xffffffce 0xffffffce 0xffffffce 0xffffffce 0xffffffce 0xffffffce 0xffffffce 0xffffffce 0xffffffce 0xffffffce 0xffffffce 0xffffffce 0xffffffce 0xffffffce 0xffffffce 0xffffffce 0xffffffce 0xffffffce 0xffffffce 0xffffffce 0xffffffce 0xffffffce 0xffffffce 0xffffffce 0xffffffce 0xffffffce 0xffffffce 0xffffffce 0xffffffce 0xffffffce 0xffffffce 0xffffffce 0xffffffce 0xffffffce 0xffffffce 0xffffffce 0xffffffce 0xffffffce 0xffffffce 0xffffffce 0xffffffce 0xffffffce 0xffffffce 0xffffffce 0xffffffce 0xffffffce 0xffffffce 0xffffffce 0xffffffce 0xffffffce 0xffffffce 0xffffffce 0xffffffce 0xffffffce 0xffffffce 0xffffffce 0xffffffce 0xffffffce 0xffffffce 0xffffffce 0xffffffce 0xffffffce 0xffffffce 0xffffffce 0xffffffce 0xffffffce 0xffffffce 0xffffffce 0xffffffce 0xffffffce 0xffffffce 0xffffffce 0xffffffce 0xffffffce 0xffffffce 0xffffffce 0xffffffce 0xffffffce 0xffffffce 0xffffffce 0xffffffce 0xffffffce 0xffffffce 0xffffffce 0xffffffce 0xffffffce 0xffffffce 0xffffffce 0xffffffce 0xffffffce 0xffffffce 0xffffffce 0xffffffce 0xffffffce 0xffffffce 0xffffffce 0xffffffce 0xffffffce 0xffffffce 0xffffffce 0xffffffce 0xffffffce 0xffffffce 0xffffffce 0xffffffce 0xffffffce 0xffffffce 0xffffffce 0xffffffce 0xffffffce 0xffffffce 0xffffffce 0xffffffce 0xffffffce 0xffffffce 0xffffffce 0xffffffce 0xffffffce 0xffffffce 0xffffffce 0xffffffce 0xffffffce 0xffffffce 0xffffffce 0xffffffce 0xffffffce 0xffffffce 0xffffffce 0xffffffce 0xffffffce 0xffffffce 0xffffffce 0xffffffce 0xffffffce 0xffffffce 0xffffffce 0xffffffce 0xffffffce 0xffffffce 0xffffffce 0xffffffce 0xffffffce 0xffffffce 0xffffffce 0xffffffce 0xffffffce 0xffffffce 0xffffffce 0xffffffce 0xffffffce 0xffffffce 0xffffffce 0xffffffce 0xffffffce 0xffffffce 0xffffffce 0xffffffce 0xffffffce 0xffffffce 0xffffffce 0xffffffce 0xffffffce 0xffffffce 0xffffffce 0xffffffce 0xffffffce 0xffffffce 0xffffffce 0xffffffce 0xffffffce 0xffffffce 0xffffffce 0xffffffce 0xffffffce 0xffffffce 0xffffffce 0xffffffce 0xffffffce 0xffffffce 0xffffffce 0xffffffce 0xffffffce 0xffffffce 0xffffffce 0xffffffce 0xffffffce 0xffffffce 0xffffffce 0xffffffce 0xffffffce 0xffffffce 0xffffffce 0xffffffce 0xffffffce 0xffffffce 0xffffffce 0xffffffce 0xffffffce 0xffffffce 0xffffffce 0xffffffce 0xffffffce 0xffffffce 0xffffffce 0xffffffce 0xffffffce 0xffffffce 0xffffffce 0xffffffce 0xffffffce 0xffffffce 0xffffffce 0xffffffce 0xffffffce 0xffffffce 0xffffffce 0xffffffce 0xffffffce 0xffffffce 0xffffffce 0xffffffce 0xffffffce 0xffffffce 0xffffffce 0xffffffce 0xffffffce 0xffffffce 0xffffffce 0xffffffce 0xffffffce 0xffffffce 0xffffffce 0xffffffce 0xffffffce 0xffffffce 0xffffffce 0xffffffce 0xffffffce 0xffffffce 0xffffffce 0xffffffce 0xffffffce 0xffffffce 0xffffffce 0xffffffce 0xffffffce 0xffffffce 0xffffffce 0xffffffce 0xffffffce 0xffffffce 0xffffffce 0xffffffce 0xffffffce 0xffffffce 0xffffffce 0xffffffce 0xffffffce 0xffffffce 0xffffffce 0xffffffce 0xffffffce 0xffffffce 0xffffffce 0xffffffce 0xffffffce 0xffffffce 0xffffffce 0xffffffce 0xffffffce 0xffffffce 0xffffffce 0xffffffce 0xffffffce 0xffffffce 0xffffffce 0xffffffce 0xffffffce 0xffffffce 0xffffffce 0xffffffce 0xffffffce 0xffffffce 0xffffffce 0xffffffce 0xffffffce 0xffffffce 0xffffffce 0xffffffce 0xffffffce 0xffffffce 0xffffffce 0xffffffce 0xffffffce 0xffffffce 0xffffffce 0xffffffce 0xffffffce 0xffffffce 0xffffffce 0xffffffce 0xffffffce 0xffffffce 0xffffffce 0xffffffce 0xffffffce 0xffffffce 0xffffffce 0xffffffce 0xffffffce 0xffffffce 0xffffffce 0xffffffce 0xffffffce 0xffffffce 0xffffffce 0xffffffce 0xffffffce 0xffffffce 0xffffffce 0xffffffce 0xffffffce 0xffffffce 0xffffffce 0xffffffce 0xffffffce 0xffffffce 0xffffffce 0xffffffce 0xffffffce 0xffffffce 0xffffffce 0xffffffce 0xffffffce 0xffffffce 0xffffffce 0xffffffce 0xffffffce 0xffffffce 0xffffffce 0xffffffce 0xffffffce 0xffffffce 0xffffffce 0xffffffce 0xffffffce 0xffffffce 0xffffffce 0xffffffb5 0xffffffb5 0xffffffb5>;
			PS_Config_Diff_Test_Frame = <0x32>;
		};
	};
};

&i2c3 {
	status = "okay";
	clock-frequency = <400000>;
	nxp@28 {
		compatible = "qcom,nq-nci";
		reg = <0x28>;
		qcom,nq-irq = <&pio 6 0>;
		interrupt-parent = <&pio>;
		interrupts = <6 IRQ_TYPE_LEVEL_HIGH 6 0>;
		qcom,nq-ven = <&pio 159 0>;
		qcom,nq-firm = <&pio 17 0>;
		qcom,nq-clkreq = <&pio 11 0>;
		interrupt-names = "nfc_irq";
		pinctrl-names = "default", "nfc_active", "nfc_suspend";
		pinctrl-0 = <&nfc_default>;
		pinctrl-1 = <&nfc_int_active &nfc_enable_active &nfc_firmwaredownload_active &nfc_clk_req_active>;
		pinctrl-2 = <&nfc_int_suspend &nfc_enable_suspend &nfc_firmwaredownload_suspend &nfc_clk_req_suspend>;
		tms,irq-gpio = <&pio 6 0>;
		tms,ven-gpio = <&pio 159 0>;
		tms,download-gpio = <&pio 17 0>;
	};
};

&pio {
	nfc_default: nfc_default {
	};
	nfc_int_active: nfc_int_active {
		pins_cmd_dat {
			pinmux = <PINMUX_GPIO6__FUNC_GPIO6>;
			slew-rate = <0>;
			drive-strength = <2>;
			bias-pull-up;
		};
	};
	nfc_int_suspend: nfc_int_suspend {
		pins_cmd_dat {
			pinmux = <PINMUX_GPIO6__FUNC_GPIO6>;
			slew-rate = <0>;
			drive-strength = <2>;
			bias-pull-up;
		};
	};
	nfc_enable_active: nfc_enable_active {
		pins_cmd_dat {
			pinmux = <PINMUX_GPIO19__FUNC_GPIO19>;
			slew-rate = <1>;
			output-high;
			drive-strength = <2>;
			bias-pull-up = <MTK_PUPD_SET_R1R0_11>;
		};
	};
	nfc_enable_suspend: nfc_enable_suspend {
		pins_cmd_dat {
			pinmux = <PINMUX_GPIO19__FUNC_GPIO19>;
			slew-rate = <1>;
			drive-strength = <2>;
			bias-disable;
		};
	};
	nfc_firmwaredownload_active: nfc_firmwaredownload_active {
		pins_cmd_dat {
			pinmux = <PINMUX_GPIO17__FUNC_GPIO17>;
			slew-rate = <1>;
			drive-strength = <2>;
			bias-pull-up;
		};
	};
	nfc_firmwaredownload_suspend: nfc_firmwaredownload_suspend {
		pins_cmd_dat {
			pinmux = <PINMUX_GPIO17__FUNC_GPIO17>;
			slew-rate = <1>;
			drive-strength = <2>;
			bias-disable;
		};
	};
	nfc_clk_req_active: nfc_clk_req_active {
		pins_cmd_dat {
			pinmux = <PINMUX_GPIO11__FUNC_SRCLKENAI0>;
			slew-rate = <0>;
			input-enable;
			drive-strength = <2>;
			bias-pull-up;
		};
	};
	nfc_clk_req_suspend: nfc_clk_req_suspend {
		pins_cmd_dat {
			pinmux = <PINMUX_GPIO11__FUNC_SRCLKENAI0>;
			slew-rate = <0>;
			input-enable;
			drive-strength = <2>;
			bias-pull-down;
		};
	};
};

&reserved_memory {
	reserve-memory-scp_share {
		compatible = "mediatek,reserve-memory-scp_share";
		no-map;
		size = <0 13631488>;
		alignment = <0 16777216>;
		alloc-ranges = <0 1073741824 0 1342177280>;
	};
};

&chosen {
	atag,videolfb-fb_base_l = <0x7e605000>;
	atag,videolfb-fb_base_h = <0>;
	atag,videolfb-islcmfound = <1>;
	atag,videolfb-islcm_inited = <0>;
	atag,videolfb-fps = <6000>;
	atag,videolfb-vramSize = <0x17e8000>;
	atag,videolfb-lcmname = "hx83112b_fhdp_dsi_cmd_auo_rt5081_drv";
};

&mtk_leds {
	compatible = "mediatek,disp-leds";
	backlight {
		led-bit = <12>;
		trans-bits = <12>;
		gate_enable = <1>;
		min-brightness = <1>;
		max-brightness = <4095>;
		max-hw-brightness = <4095>;
		led_mode = <4>;
	};
};

&utos {
	microtrust,real-drv = <1>;
};

&odm {
	led0: led@0 {
		compatible = "mediatek,red";
		led_mode = <0>;
		data = <1>;
		pwm_config = <0 0 0 0 0>;
	};
	led1: led@1 {
		compatible = "mediatek,green";
		led_mode = <0>;
		data = <1>;
		pwm_config = <0 0 0 0 0>;
	};
	led2: led@2 {
		compatible = "mediatek,blue";
		led_mode = <0>;
		data = <1>;
		pwm_config = <0 0 0 0 0>;
	};
	led3: led@3 {
		compatible = "mediatek,jogball-backlight";
		led_mode = <0>;
		data = <1>;
		pwm_config = <0 0 0 0 0>;
	};
	led4: led@4 {
		compatible = "mediatek,keyboard-backlight";
		led_mode = <0>;
		data = <1>;
		pwm_config = <0 0 0 0 0>;
	};
	led5: led@5 {
		compatible = "mediatek,button-backlight";
		led_mode = <0>;
		data = <1>;
		pwm_config = <0 0 0 0 0>;
	};
	led6: led@6 {
		compatible = "mediatek,lcd-backlight";
		led_mode = <4>;
		data = <1>;
		pwm_config = <0 3 0 0 0>;
	};
	vibrator0: vibrator@0 {
		compatible = "mediatek,vibrator";
		vib_timer = <25>;
		vib_limit = <9>;
		vib_vol = <9>;
	};
};

&i2c2 {
	clock-frequency = <400000>;
	mtk-usb@60 {
		compatible = "mediatek,mtk-usb";
		reg = <0x60>;
		status = "okay";
	};
};

&accdet {
	accdet-mic-vol = <6>;
	headset-mode-setting = <1280 1280 1 496 2048 2048 32 68 0 0 14 0 0 0 0>;
	accdet-plugout-debounce = <1>;
	accdet-mic-mode = <1>;
	headset-eint-level-pol = <8>;
	headset-three-key-threshold = <0 80 220 400>;
	headset-three-key-threshold-CDD = <0 121 192 600>;
	headset-four-key-threshold = <0 58 121 192 400>;
	status = "okay";
};

&keypad {
	pinctrl-names = "default";
	pinctrl-0 = <&kpd_pins_default>;
};

&pio {
	kpd_pins_default: kpdgpiodefault {
		pins_cmd_dat {
			pinmux = <PINMUX_GPIO93__FUNC_KPCOL0>;
			bias-pull-up = <MTK_PUPD_SET_R1R0_10>;
			input-enable;
			input-schmitt-enable;
		};
	};
};

&mt6370 {
	interrupt-parent = <&pio>;
	interrupts = <20 IRQ_TYPE_LEVEL_LOW 20 0>;
};

&mt6370_typec {
	mt6370pd-intr-gpios = <&pio 41 0>;
};

&thermal_message {
	board-sensor = "VIRTUAL-SENSOR";
};

&pio {
	consys_pins_default: consys_default {
	};
	gpslna_pins_init: gpslna@0 {
		pins_cmd_dat {
			pinmux = <PINMUX_GPIO94__FUNC_GPIO94>;
			slew-rate = <0>;
			bias-disable;
			output-low;
		};
	};
	gpslna_pins_oh: gpslna@1 {
		pins_cmd_dat {
			pinmux = <PINMUX_GPIO94__FUNC_GPIO94>;
			slew-rate = <1>;
			output-high;
		};
	};
	gpslna_pins_ol: gpslna@2 {
		pins_cmd_dat {
			pinmux = <PINMUX_GPIO94__FUNC_GPIO94>;
			slew-rate = <1>;
			output-low;
		};
	};
};

&consys {
	pinctrl-names = "default", "gps_lna_state_init", "gps_lna_state_oh", "gps_lna_state_ol";
	pinctrl-0 = <&consys_pins_default>;
	pinctrl-1 = <&gpslna_pins_init>;
	pinctrl-2 = <&gpslna_pins_oh>;
	pinctrl-3 = <&gpslna_pins_ol>;
	status = "okay";
};

&irtx_pwm {
	pinctrl-names = "irtx_gpio_led_default", "irtx_gpio_led_set";
	pinctrl-0 = <&irtx_gpio_led_default>;
	pinctrl-1 = <&irtx_gpio_led_set>;
	status = "okay";
};

&pio {
	irtx_gpio_led_default: irtx_gpio_led_def@gpio12 {
		pins_cmd_dat {
			pinmux = <PINMUX_GPIO12__FUNC_GPIO12>;
			slew-rate = <1>;
			bias-disable;
			output-low;
			input-schmitt-enable = <0>;
		};
	};
	irtx_gpio_led_set: irtx_gpio_led_set@gpio12 {
		pins_cmd_dat {
			pinmux = <PINMUX_GPIO12__FUNC_PWM0>;
			slew-rate = <1>;
			output-high;
		};
	};
};

&pio {
	mtkfb_pins_lcm_rst_out1_gpio: lcm_rst_out1_gpio {
		pins_cmd_dat {
			pinmux = <PINMUX_GPIO45__FUNC_GPIO45>;
			slew-rate = <1>;
			output-high;
		};
	};
	mtkfb_pins_lcm_rst_out0_gpio: lcm_rst_out0_gpio {
		pins_cmd_dat {
			pinmux = <PINMUX_GPIO45__FUNC_GPIO45>;
			slew-rate = <1>;
			output-low;
		};
	};
	mtkfb_pins_lcm_dsi_te: lcm_dsi_te {
		pins_cmd_dat {
			pinmux = <PINMUX_GPIO44__FUNC_DSI_TE>;
		};
	};
	mtkfb_pins_lcm_err_flag: lcm_err_flag {
		pins_cmd_dat {
			pinmux = <PINMUX_GPIO9__FUNC_GPIO9>;
			slew-rate = <0>;
			bias-disable;
		};
	};
};

&mtkfb {
	pinctrl-names = "lcm_rst_out1_gpio", "lcm_rst_out0_gpio", "mode_te_te", "err_flag_init";
	pinctrl-0 = <&mtkfb_pins_lcm_rst_out1_gpio>;
	pinctrl-1 = <&mtkfb_pins_lcm_rst_out0_gpio>;
	pinctrl-2 = <&mtkfb_pins_lcm_dsi_te>;
	pinctrl-3 = <&mtkfb_pins_lcm_err_flag>;
	status = "okay";
};

&dispsys_config {
	pinctrl-names = "lcm_rst_out1_gpio", "lcm_rst_out0_gpio", "mode_te_te", "err_flag_init";
	pinctrl-0 = <&mtkfb_pins_lcm_rst_out1_gpio>;
	pinctrl-1 = <&mtkfb_pins_lcm_rst_out0_gpio>;
	pinctrl-2 = <&mtkfb_pins_lcm_dsi_te>;
	pinctrl-3 = <&mtkfb_pins_lcm_err_flag>;
	status = "okay";
};

&dsi0 {
	status = "okay";
	#address-cells = <1>;
	#size-cells = <0>;
	panel1@0 {
		compatible = "dsi_panel_c3u,lcm";
		reg = <0x0>;
		reset-gpios = <&pio 45 0>;
		enp-gpios = <&pio 169 0>;
		enn-gpios = <&pio 165 0>;
		mi,esd-err-irq-gpio = <&pio 9 0x2002>;
		status = "okay";
		port {
			panel_in1: endpoint {
				remote-endpoint = <&dsi_out>;
			};
		};
	};
	ports {
		port {
			dsi_out: endpoint {
				remote-endpoint = <&panel_in1>;
			};
		};
	};
};

&i2c0 {
	bias_lcd: bias_lcd@3e {
		compatible = "bias,lcd_bias";
		reg = <0x3e>;
		status = "okay";
	};
};

&i2c7 {
	mt6660: mt6660@34 {
		compatible = "mediatek,mt6660";
		#sound-dai-cells = <0>;
		reg = <0x34>;
		status = "disabled";
	};
};

&sound {
	mediatek,speaker-codec {
		sound-dai = <&mt6660>;
	};
};

&mtkheap_region_svp {
	status = "ok";
};

&mtkheap_region_wfd {
	status = "ok";
};

&mtee_svp {
	mtee: MTEE {
		compatible = "mediatek,mtk_svp_on_mtee_support";
	};
	svp: SecureVideoPath {
		compatible = "mediatek,mtk_sec_video_path_support";
	};
};

#include "gale/cust.dtsi"

&pio {
	camera0_mclk_2mA: camera0_mclk_2mA@gpio100 {
		pins_cmd_dat {
			pinmux = <PINMUX_GPIO100__FUNC_CMMCLK1>;
			drive-strength = <2>;
		};
	};
	camera0_mclk_4mA: camera0_mclk_4mA@gpio100 {
		pins_cmd_dat {
			pinmux = <PINMUX_GPIO100__FUNC_CMMCLK1>;
			drive-strength = <4>;
		};
	};
	camera0_mclk_6mA: camera0_mclk_6mA@gpio100 {
		pins_cmd_dat {
			pinmux = <PINMUX_GPIO100__FUNC_CMMCLK1>;
			drive-strength = <6>;
		};
	};
	camera0_mclk_8mA: camera0_mclk_8mA@gpio100 {
		pins_cmd_dat {
			pinmux = <PINMUX_GPIO100__FUNC_CMMCLK1>;
			drive-strength = <7>;
		};
	};
	camera0_mclk_off: camera0_mclk_gpio_mode@gpio100 {
		pins_cmd_dat {
			pinmux = <PINMUX_GPIO100__FUNC_GPIO100>;
			drive-strength = <4>;
		};
	};
	camera1_mclk_2mA: camera1_mclk_2mA@gpio99 {
		pins_cmd_dat {
			pinmux = <PINMUX_GPIO99__FUNC_CMMCLK0>;
			drive-strength = <2>;
		};
	};
	camera1_mclk_4mA: camera1_mclk_4mA@gpio99 {
		pins_cmd_dat {
			pinmux = <PINMUX_GPIO99__FUNC_CMMCLK0>;
			drive-strength = <4>;
		};
	};
	camera1_mclk_6mA: camera1_mclk_6mA@gpio99 {
		pins_cmd_dat {
			pinmux = <PINMUX_GPIO99__FUNC_CMMCLK0>;
			drive-strength = <6>;
		};
	};
	camera1_mclk_8mA: camera1_mclk_8mA@gpio99 {
		pins_cmd_dat {
			pinmux = <PINMUX_GPIO99__FUNC_CMMCLK0>;
			drive-strength = <7>;
		};
	};
	camera1_mclk_off: camera1_mclk_gpio_mode@gpio99 {
		pins_cmd_dat {
			pinmux = <PINMUX_GPIO99__FUNC_GPIO99>;
			drive-strength = <4>;
		};
	};
	camera2_mclk_2mA: camera2_mclk_2mA@gpio108 {
		pins_cmd_dat {
			pinmux = <PINMUX_GPIO108__FUNC_CMMCLK2>;
			drive-strength = <2>;
		};
	};
	camera2_mclk_4mA: camera2_mclk_4mA@gpio108 {
		pins_cmd_dat {
			pinmux = <PINMUX_GPIO108__FUNC_CMMCLK2>;
			drive-strength = <4>;
		};
	};
	camera2_mclk_6mA: camera2_mclk_6mA@gpio108 {
		pins_cmd_dat {
			pinmux = <PINMUX_GPIO108__FUNC_CMMCLK2>;
			drive-strength = <6>;
		};
	};
	camera2_mclk_8mA: camera2_mclk_8mA@gpio108 {
		pins_cmd_dat {
			pinmux = <PINMUX_GPIO108__FUNC_CMMCLK2>;
			drive-strength = <7>;
		};
	};
	camera2_mclk_off: camera2_mclk_gpio_mode@gpio108 {
		pins_cmd_dat {
			pinmux = <PINMUX_GPIO108__FUNC_GPIO108>;
			drive-strength = <4>;
		};
	};
	camera0_rst_low: camera0_rst_output_low@gpio102 {
		pins_cmd_dat {
			pinmux = <PINMUX_GPIO102__FUNC_GPIO102>;
			output-low;
		};
	};
	camera0_rst_high: camera0_rst_output_high@gpio102 {
		pins_cmd_dat {
			pinmux = <PINMUX_GPIO102__FUNC_GPIO102>;
			output-high;
		};
	};
	camera0_pdn_low: camera0_pdn_output_low@gpio98 {
		pins_cmd_dat {
			pinmux = <PINMUX_GPIO98__FUNC_GPIO98>;
			output-low;
		};
	};
	camera0_pdn_high: camera0_pdn_output_high@gpio98 {
		pins_cmd_dat {
			pinmux = <PINMUX_GPIO98__FUNC_GPIO98>;
			output-high;
		};
	};
	camera1_rst_low: camera1_rst_output_low@gpio101 {
		pins_cmd_dat {
			pinmux = <PINMUX_GPIO101__FUNC_GPIO101>;
			output-low;
		};
	};
	camera1_rst_high: camera1_rst_output_high@gpio101 {
		pins_cmd_dat {
			pinmux = <PINMUX_GPIO101__FUNC_GPIO101>;
			output-high;
		};
	};
	camera1_pdn_low: camera1_pdn_output_low@gpio97 {
		pins_cmd_dat {
			pinmux = <PINMUX_GPIO97__FUNC_GPIO97>;
			slew-rate = <1>;
			output-low;
		};
	};
	camera1_pdn_high: camera1_pdn_output_high@gpio97 {
		pins_cmd_dat {
			pinmux = <PINMUX_GPIO97__FUNC_GPIO97>;
			output-high;
		};
	};
	camera2_rst_low: camera2_rst_output_low@gpio109 {
		pins_cmd_dat {
			pinmux = <PINMUX_GPIO109__FUNC_GPIO109>;
			output-low;
		};
	};
	camera2_rst_high: camera2_rst_output_high@gpio109 {
		pins_cmd_dat {
			pinmux = <PINMUX_GPIO109__FUNC_GPIO109>;
			output-high;
		};
	};
	camera2_pdn_low: camera2_pdn_output_low@gpio110 {
		pins_cmd_dat {
			pinmux = <PINMUX_GPIO110__FUNC_GPIO110>;
			output-low;
		};
	};
	camera2_pdn_high: camera2_pdn_output_high@gpio110 {
		pins_cmd_dat {
			pinmux = <PINMUX_GPIO110__FUNC_GPIO110>;
			output-high;
		};
	};
	camera0_vcamd_off: camera0_vcamd_output_low@gpio178 {
		pins_cmd_dat {
			pinmux = <PINMUX_GPIO178__FUNC_GPIO178>;
			output-low;
		};
	};
	camera0_vcamd_on: camera0_vcamd_output_high@gpio178 {
		pins_cmd_dat {
			pinmux = <PINMUX_GPIO178__FUNC_GPIO178>;
			output-high;
		};
	};
	camera1_vcamd_off: camera1_vcamd_output_low@gpio179 {
		pins_cmd_dat {
			pinmux = <PINMUX_GPIO179__FUNC_GPIO179>;
			output-low;
		};
	};
	camera1_vcamd_on: camera1_vcamd_output_high@gpio179 {
		pins_cmd_dat {
			pinmux = <PINMUX_GPIO179__FUNC_GPIO179>;
			output-high;
		};
	};
	camera_pins_default: camdefault {
	};
	flashlight_pins_default: flashlightdefault {
	};
	flashlight_pins_en_output1: flashlightenoutput1 {
		pins_cmd_dat {
			pinmux = <PINMUX_GPIO151__FUNC_GPIO151>;
			slew-rate = <1>;
			output-high;
		};
	};
	flashlight_pins_en_output0: flashlightenoutput0 {
		pins_cmd_dat {
			pinmux = <PINMUX_GPIO151__FUNC_GPIO151>;
			slew-rate = <1>;
			output-low;
		};
	};
	flashlight_pins_sel_output1: flashlightseloutput1 {
		pins_cmd_dat {
			pinmux = <PINMUX_GPIO30__FUNC_GPIO30>;
			slew-rate = <1>;
			output-high;
		};
	};
	flashlight_pins_sel_output0: flashlightseloutput0 {
		pins_cmd_dat {
			pinmux = <PINMUX_GPIO30__FUNC_GPIO30>;
			slew-rate = <1>;
			output-low;
		};
	};
};

&kd_camera_hw1 {
	pinctrl-names = "default", "cam0_rst0", "cam0_rst1", "cam0_pnd0", "cam0_pnd1", "cam1_rst0", "cam1_rst1", "cam1_pnd0", "cam1_pnd1", "cam2_rst0", "cam2_rst1", "cam2_pnd0", "cam2_pnd1", "cam0_vcamd_on", "cam0_vcamd_off", "cam1_vcamd_on", "cam1_vcamd_off", "cam0_mclk_off", "cam0_mclk_2mA", "cam0_mclk_4mA", "cam0_mclk_6mA", "cam0_mclk_8mA", "cam1_mclk_off", "cam1_mclk_2mA", "cam1_mclk_4mA", "cam1_mclk_6mA", "cam1_mclk_8mA", "cam2_mclk_off", "cam2_mclk_2mA", "cam2_mclk_4mA", "cam2_mclk_6mA", "cam2_mclk_8mA";
	pinctrl-0 = <&camera_pins_default>;
	pinctrl-1 = <&camera0_rst_low>;
	pinctrl-2 = <&camera0_rst_high>;
	pinctrl-3 = <&camera0_pdn_low>;
	pinctrl-4 = <&camera0_pdn_high>;
	pinctrl-5 = <&camera1_rst_low>;
	pinctrl-6 = <&camera1_rst_high>;
	pinctrl-7 = <&camera1_pdn_low>;
	pinctrl-8 = <&camera1_pdn_high>;
	pinctrl-9 = <&camera2_rst_low>;
	pinctrl-10 = <&camera2_rst_high>;
	pinctrl-11 = <&camera2_pdn_low>;
	pinctrl-12 = <&camera2_pdn_high>;
	pinctrl-13 = <&camera0_vcamd_on>;
	pinctrl-14 = <&camera0_vcamd_off>;
	pinctrl-15 = <&camera1_vcamd_on>;
	pinctrl-16 = <&camera1_vcamd_off>;
	pinctrl-17 = <&camera0_mclk_off>;
	pinctrl-18 = <&camera0_mclk_2mA>;
	pinctrl-19 = <&camera0_mclk_4mA>;
	pinctrl-20 = <&camera0_mclk_6mA>;
	pinctrl-21 = <&camera0_mclk_8mA>;
	pinctrl-22 = <&camera1_mclk_off>;
	pinctrl-23 = <&camera1_mclk_2mA>;
	pinctrl-24 = <&camera1_mclk_4mA>;
	pinctrl-25 = <&camera1_mclk_6mA>;
	pinctrl-26 = <&camera1_mclk_8mA>;
	pinctrl-27 = <&camera2_mclk_off>;
	pinctrl-28 = <&camera2_mclk_2mA>;
	pinctrl-29 = <&camera2_mclk_4mA>;
	pinctrl-30 = <&camera2_mclk_6mA>;
	pinctrl-31 = <&camera2_mclk_8mA>;
	cam0_vcama-supply = <&mt_pmic_vcama2_ldo_reg>;
	cam1_vcama-supply = <&mt_pmic_vcama1_ldo_reg>;
	cam2_vcama-supply = <&mt_pmic_vcama1_ldo_reg>;
	cam0_vcamd-supply = <&mt_pmic_vcamd_ldo_reg>;
	cam0_vcamio-supply = <&mt_pmic_vcamio_ldo_reg>;
	cam1_vcamio-supply = <&mt_pmic_vcamio_ldo_reg>;
	cam2_vcamio-supply = <&mt_pmic_vcamio_ldo_reg>;
	cam0_vcamaf-supply = <&mt_pmic_vio28_ldo_reg>;
	cam0_enable_sensor = "s5kjns_sunny_main_ii_mipi_raw s5kjns_truly_main_iii_mipi_raw ov50d40_truly_main_i_mipi_raw";
	cam1_enable_sensor = "ov8856_aac_front_i_mipi_raw  ov8856_truly_front_ii_mipi_raw";
	cam2_enable_sensor = "sc202cs_sunny_marco_i_mipi_raw sc202cs_aac_marco_ii_mipi_raw";
	status = "okay";
};

&flashlights_ocp8132 {
	pinctrl-names = "default", "hw_ch0_high", "hw_ch0_low", "hw_ch1_high", "hw_ch1_low";
	pinctrl-0 = <&flashlight_pins_default>;
	pinctrl-1 = <&flashlight_pins_en_output1>;
	pinctrl-2 = <&flashlight_pins_en_output0>;
	pinctrl-3 = <&flashlight_pins_sel_output1>;
	pinctrl-4 = <&flashlight_pins_sel_output0>;
	status = "okay";
};

&spi2 {
	#address-cells = <1>;
	#size-cells = <0>;
	fpc_tee@2 {
		compatible = "fpc,fpc_spi";
		reg = <0x0>;
		fpc,enable-wakeup;
		spi-max-frequency = <0x989680>;
		netlink-event = <31>;
		VFP-supply = <&mt_pmic_vldo28_ldo_reg>;
		avdd-supply = <&mt_pmic_vldo28_ldo_reg>;
		status = "okay";
	};
};

&fpsensor_finger {
	pinctrl-names = "fpsensor_fpc_rst_low", "fpsensor_fpc_rst_high", "fpsensor_fpc_cs_low", "fpsensor_fpc_cs_high";
	pinctrl-0 = <&fpsensor_fpc_rst_low>;
	pinctrl-1 = <&fpsensor_fpc_rst_high>;
	pinctrl-2 = <&fpsensor_fpc_cs_low>;
	pinctrl-3 = <&fpsensor_fpc_cs_high>;
	VFP-supply = <&mt_pmic_vldo28_ldo_reg>;
	status = "okay";
};

&pio {
	fpsensor_fpc_rst_low: fpsensor_fpc_rst_low {
		pins_cmd_dat {
			pinmux = <PINMUX_GPIO31__FUNC_GPIO31>;
			slew-rate = <1>;
			output-low;
		};
	};
	fpsensor_fpc_cs_low: fpsensor_fpc_cs_low {
		pins_cmd_dat {
			pinmux = <PINMUX_GPIO25__FUNC_GPIO25>;
			slew-rate = <1>;
			output-low;
		};
	};
	fpsensor_fpc_rst_high: fpsensor_fpc_rst_high {
		pins_cmd_dat {
			pinmux = <PINMUX_GPIO31__FUNC_GPIO31>;
			slew-rate = <1>;
			output-high;
		};
	};
	fpsensor_fpc_cs_high: fpsensor_fpc_cs_high {
		pins_cmd_dat {
			pinmux = <PINMUX_GPIO25__FUNC_SPI2_CSB>;
			slew-rate = <1>;
			bias-pull-up;
		};
	};
};

&silead_fp {
	pinctrl-names = "default", "rst-low", "rst-high", "irq-init", "spi-default", "irq_rst-low", "irq_rst-high";
	pinctrl-0 = <&silfp_default>;
	pinctrl-1 = <&silfp_rst_low>;
	pinctrl-2 = <&silfp_rst_high>;
	pinctrl-3 = <&silfp_irq>;
	pinctrl-4 = <&fingerprint_pins_default>;
	pinctrl-5 = <&silfp_irq_rst_low>;
	pinctrl-6 = <&silfp_irq_rst_high>;
	avdd-supply = <&mt_pmic_vldo28_ldo_reg>;
	status = "okay";
};

&pio {
	fingerprint_pins_default: fp_default {
		pins_cmd_dat {
			pinmux = <PINMUX_GPIO25__FUNC_SPI2_CSB>;
			slew-rate = <1>;
			bias-pull-up;
		};
		pins_cmd2_dat {
			pinmux = <PINMUX_GPIO27__FUNC_SPI2_CLK>;
			slew-rate = <1>;
			bias-pull-down;
		};
		pins_cmd3_dat {
			pinmux = <PINMUX_GPIO28__FUNC_SPI2_MI>;
			slew-rate = <0>;
			bias-pull-down;
		};
		pins_cmd4_dat {
			pinmux = <PINMUX_GPIO26__FUNC_SPI2_MO>;
			slew-rate = <1>;
			bias-pull-down;
		};
	};
};

&pio {
	silfp_default: silfpdefault {
	};
	silfp_rst_high: state_reset_high {
		pins_cmd_dat {
			pinmux = <PINMUX_GPIO31__FUNC_GPIO31>;
			slew-rate = <1>;
			output-high;
		};
	};
	silfp_rst_low: state_reset_low {
		pins_cmd_dat {
			pinmux = <PINMUX_GPIO31__FUNC_GPIO31>;
			slew-rate = <1>;
			output-low;
		};
	};
	silfp_irq_rst_high: state_irq_to_reset_high {
		pins_cmd_dat {
			pinmux = <PINMUX_GPIO8__FUNC_GPIO8>;
			slew-rate = <1>;
			output-high;
		};
	};
	silfp_irq_rst_low: state_irq_to_reset_low {
		pins_cmd_dat {
			pinmux = <PINMUX_GPIO8__FUNC_GPIO8>;
			slew-rate = <1>;
			output-low;
		};
	};
	silfp_irq: fp_eint@8 {
		pins_cmd_dat {
			pinmux = <PINMUX_GPIO8__FUNC_GPIO8>;
			slew-rate = <0>;
			bias-pull-down = <0>;
		};
	};
};

&odm {
	fs15xx: audio_fs15xx {
		compatible = "foursemi,fs15xx";
		status = "okay";
		fsm,dev-type = <1>;
		fsm,id-gpio = <&pio 150 0>;
		fsm,cmd-gpio = <&pio 160 0>;
		fsm,mod-gpio = <&pio 153 0>;
		pinctrl-names = "fs15xx_id_default", "fs15xx_id_active", "fs15xx_cmd_default", "fs15xx_mod_default";
		pinctrl-0 = <&fs15xx_id_default>;
		pinctrl-1 = <&fs15xx_id_active>;
		pinctrl-2 = <&fs15xx_cmd_default>;
		pinctrl-3 = <&fs15xx_mod_default>;
	};
};

&pio {
	fs15xx_id_default: fs15xx_id_default {
		pins_cmd_dat {
			pinmux = <PINMUX_GPIO150__FUNC_GPIO150>;
			slew-rate = <0>;
			bias-disable;
			output-low;
		};
	};
	fs15xx_id_active: fs15xx_id_active {
		pins_cmd_dat {
			pinmux = <PINMUX_GPIO150__FUNC_GPIO150>;
			slew-rate = <0>;
			bias-pull-up;
		};
	};
	fs15xx_cmd_default: fs15xx_cmd_default {
		pins_cmd_dat {
			pinmux = <PINMUX_GPIO160__FUNC_GPIO160>;
			slew-rate = <1>;
			output-low;
		};
	};
	fs15xx_mod_default: fs15xx_mod_default {
		pins_cmd_dat {
			pinmux = <PINMUX_GPIO153__FUNC_GPIO153>;
			slew-rate = <1>;
			output-low;
		};
	};
};
